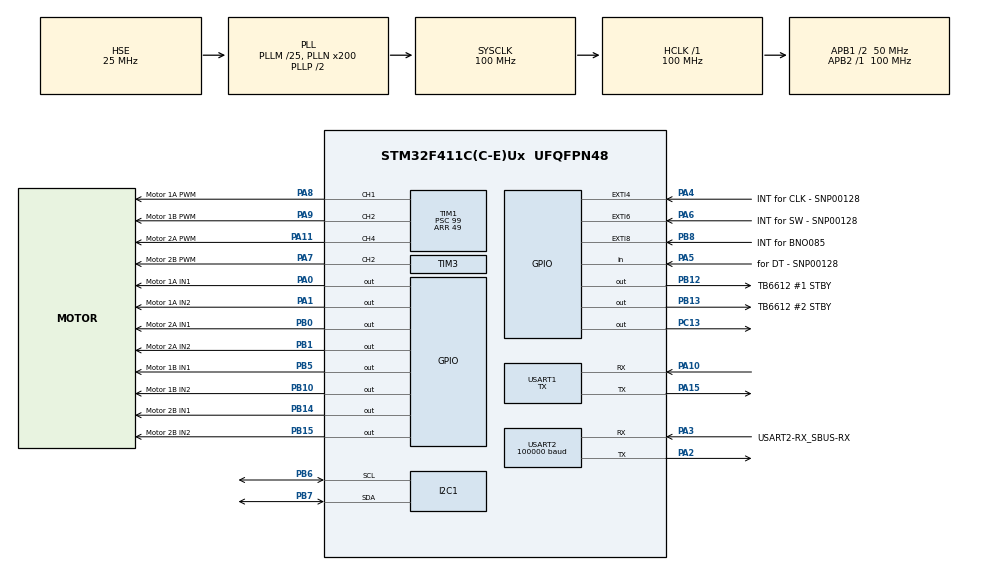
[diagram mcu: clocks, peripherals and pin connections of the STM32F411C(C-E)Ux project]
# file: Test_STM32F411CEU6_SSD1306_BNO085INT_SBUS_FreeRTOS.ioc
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Dma.Request0=USART2_RX
Dma.USART2_RX.0.Direction=DMA_PERIPH_TO_MEMORY
Dma.USART2_RX.0.FIFOMode=DMA_FIFOMODE_DISABLE
Dma.USART2_RX.0.Instance=DMA1_Stream5
Dma.USART2_RX.0.MemDataAlignment=DMA_MDATAALIGN_BYTE
Dma.USART2_RX.0.MemInc=DMA_MINC_ENABLE
Dma.USART2_RX.0.Mode=DMA_CIRCULAR
Dma.USART2_RX.0.PeriphDataAlignment=DMA_PDATAALIGN_BYTE
Dma.USART2_RX.0.PeriphInc=DMA_PINC_DISABLE
Dma.USART2_RX.0.Priority=DMA_PRIORITY_HIGH
FREERTOS.Mutexes01=CompassMutex,Dynamic,NULL,Depleted;I2C1Mutex,Dynamic,NULL,Depleted;EncoderMutex,Dynamic,NULL,Depleted;UARTMutex,Dynamic,NULL,Depleted;ModeMutex,Dynamic,NULL,Depleted;EEPROMMutex,Dynamic,NULL,Available
FREERTOS.Tasks01=defaultTask,32,256,StartDefaultTask,Default,NULL,Dynamic,NULL,NULL;CompassTask,40,256,StartCompassTask,Default,NULL,Dynamic,NULL,NULL;DisplayTask,8,320,StartDisplayTask,Default,NULL,Dynamic,NULL,NULL;EncoderTask,24,128,StartEncoderTask,Default,NULL,Dynamic,NULL,NULL
FREERTOS.configCHECK_FOR_STACK_OVERFLOW=1
FREERTOS.configENABLE_BACKWARD_COMPATIBILITY=0
FREERTOS.configGENERATE_RUN_TIME_STATS=1
FREERTOS.configUSE_APPLICATION_TASK_TAG=1
FREERTOS.configUSE_NEWLIB_REENTRANT=1
I2C1.DutyCycle=I2C_DUTYCYCLE_16_9
I2C1.I2C_Mode=I2C_Fast
IWDG.Prescaler=IWDG_PRESCALER_64
IWDG.Reload=3125
Mcu.Family=STM32F4
Mcu.Name=STM32F411C(C-E)Ux
Mcu.Package=UFQFPN48
NVIC.DMA1_Stream5_IRQn=true\:5\:0\:false\:false\:true\:true\:false\:true\:true
NVIC.EXTI4_IRQn=true\:5\:0\:false\:false\:true\:true\:true\:true\:true
NVIC.EXTI9_5_IRQn=true\:5\:0\:false\:false\:true\:true\:true\:true\:true
NVIC.PriorityGroup=NVIC_PRIORITYGROUP_4
NVIC.TIM2_IRQn=true\:15\:0\:false\:false\:true\:false\:false\:true\:true
NVIC.TimeBase=TIM2_IRQn
NVIC.TimeBaseIP=TIM2
NVIC.USART2_IRQn=true\:5\:0\:false\:false\:true\:true\:true\:true\:true
NimaLTD.I-CUBE-EE.3.2.2.DriverJjEE=true
NimaLTD.I-CUBE-EE.3.2.2.EE_MANUAL_CONFIG=true
NimaLTD.I-CUBE-EE.3.2.2.EE_SELECTED_ADDRESS=0x08070000
NimaLTD.I-CUBE-EE.3.2.2.EE_SELECTED_PAGE_SECTOR_NUMBER=7
NimaLTD.I-CUBE-EE.3.2.2.EE_SELECTED_PAGE_SECTOR_SIZE=EE_PAGE_SECTOR_SIZE_128K
PA0-WKUP.GPIO_Label=Motor 1A IN1
PA0-WKUP.Signal=GPIO_Output
PA1.GPIO_Label=Motor 1A IN2
PA1.Signal=GPIO_Output
PA10.Mode=Asynchronous
PA10.Signal=USART1_RX
PA11.GPIO_Label=Motor 2A PWM
PA11.Signal=S_TIM1_CH4
PA13.Mode=Serial_Wire
PA13.Signal=SYS_JTMS-SWDIO
PA14.Mode=Serial_Wire
PA14.Signal=SYS_JTCK-SWCLK
PA15.Mode=Asynchronous
PA15.Signal=USART1_TX
PA2.Mode=Asynchronous
PA2.Signal=USART2_TX
PA3.GPIO_Label=USART2-RX_SBUS-RX
PA3.GPIO_PuPd=GPIO_PULLUP
PA3.Mode=Asynchronous
PA3.Signal=USART2_RX
PA4.GPIO_Label=INT for CLK - SNP00128
PA4.GPIO_ModeDefaultEXTI=GPIO_MODE_IT_RISING_FALLING
PA4.GPIO_PuPd=GPIO_PULLUP
PA4.Signal=GPXTI4
PA5.GPIO_Label=for DT - SNP00128
PA5.GPIO_PuPd=GPIO_PULLUP
PA5.Signal=GPIO_Input
PA6.GPIO_Label=INT for SW - SNP00128
PA6.GPIO_ModeDefaultEXTI=GPIO_MODE_IT_FALLING
PA6.GPIO_PuPd=GPIO_PULLUP
PA6.Signal=GPXTI6
PA7.GPIO_Label=Motor 2B PWM
PA7.Signal=S_TIM3_CH2
PA8.GPIO_Label=Motor 1A PWM
PA8.Signal=S_TIM1_CH1
PA9.GPIO_Label=Motor 1B PWM
PA9.Signal=S_TIM1_CH2
PB0.GPIO_Label=Motor 2A IN1
PB0.Signal=GPIO_Output
PB1.GPIO_Label=Motor 2A IN2
PB1.Signal=GPIO_Output
PB10.GPIO_Label=Motor 1B IN2
PB10.Signal=GPIO_Output
PB12.GPIO_Label=TB6612 \#1 STBY
PB12.Signal=GPIO_Output
PB13.GPIO_Label=TB6612 \#2 STBY
PB13.Signal=GPIO_Output
PB14.GPIO_Label=Motor 2B IN1
PB14.Signal=GPIO_Output
PB15.GPIO_Label=Motor 2B IN2
PB15.Signal=GPIO_Output
PB5.GPIO_Label=Motor 1B IN1
PB5.Signal=GPIO_Output
PB6.Mode=I2C
PB6.Signal=I2C1_SCL
PB7.Mode=I2C
PB7.Signal=I2C1_SDA
PB8.GPIO_Label=INT for BNO085
PB8.GPIO_ModeDefaultEXTI=GPIO_MODE_IT_FALLING
PB8.Signal=GPXTI8
PC13-ANTI_TAMP.Signal=GPIO_Output
PH0\ -\ OSC_IN.Mode=HSE-External-Oscillator
PH0\ -\ OSC_IN.Signal=RCC_OSC_IN
PH1\ -\ OSC_OUT.Mode=HSE-External-Oscillator
PH1\ -\ OSC_OUT.Signal=RCC_OSC_OUT
ProjectManager.HeapSize=0x200
ProjectManager.StackSize=0x400
ProjectManager.TargetToolchain=STM32CubeIDE
RCC.48MHZClocksFreq_Value=50000000
RCC.AHBFreq_Value=100000000
RCC.APB1CLKDivider=RCC_HCLK_DIV2
RCC.APB1Freq_Value=50000000
RCC.APB1TimFreq_Value=100000000
RCC.APB2Freq_Value=100000000
RCC.APB2TimFreq_Value=100000000
RCC.CortexFreq_Value=100000000
RCC.HCLKFreq_Value=100000000
RCC.HSE_VALUE=25000000
RCC.HSI_VALUE=16000000
RCC.LSE_VALUE=32768
RCC.PLLM=25
RCC.PLLN=200
RCC.PLLSourceVirtual=RCC_PLLSOURCE_HSE
RCC.SYSCLKFreq_VALUE=100000000
RCC.SYSCLKSource=RCC_SYSCLKSOURCE_PLLCLK
RCC.VCOOutputFreq_Value=200000000
SH.S_TIM1_CH1.0=TIM1_CH1,PWM Generation1 CH1
SH.S_TIM1_CH2.0=TIM1_CH2,PWM Generation2 CH2
SH.S_TIM1_CH4.0=TIM1_CH4,PWM Generation4 CH4
SH.S_TIM3_CH2.0=TIM3_CH2,PWM Generation2 CH2
TIM1.Channel-PWM\ Generation1\ CH1=TIM_CHANNEL_1
TIM1.Channel-PWM\ Generation2\ CH2=TIM_CHANNEL_2
TIM1.Channel-PWM\ Generation4\ CH4=TIM_CHANNEL_4
TIM1.Period=49
TIM1.Prescaler=99
TIM3.Channel-PWM\ Generation2\ CH2=TIM_CHANNEL_2
TIM3.Period=49
TIM3.Prescaler=99
USART1.Mode=MODE_TX
USART1.VirtualMode=VM_ASYNC
USART2.BaudRate=100000
USART2.Mode=MODE_RX
USART2.Parity=PARITY_EVEN
USART2.StopBits=STOPBITS_2
USART2.VirtualMode=VM_ASYNC
USART2.WordLength=WORDLENGTH_9B
VP_FREERTOS_VS_CMSIS_V2.Mode=CMSIS_V2
VP_IWDG_VS_IWDG.Mode=IWDG_Activate
VP_NimaLTD.I-CUBE-EE_VS_DriverJjEE_1.0.0_3.2.2.Mode=DriverJjEE
VP_SYS_VS_tim2.Mode=TIM2
board=custom

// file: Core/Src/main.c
/* USER CODE BEGIN Header */
/**
 ******************************************************************************
 * @file           : main.c
 * @brief          : Main program body
 ******************************************************************************
 * @attention
 *
 * Copyright (c) 2025 STMicroelectronics.
 * All rights reserved.
 *
 * This software is licensed under terms that can be found in the LICENSE file
 * in the root directory of this software component.
 * If no LICENSE file comes with this software, it is provided AS-IS.
 *
 ******************************************************************************
 */

// Compiler optimizations for performance-critical functions
#pragma GCC optimize("O3")
#pragma GCC target("thumb")
/* USER CODE END Header */
#include "main.h"
#include "cmsis_os.h"

/* USER CODE BEGIN Includes */
#include "ssd1306.h"
#include "fonts.h"
#include <string.h>
#include <stdio.h>
#include <stdarg.h>
#include <math.h>
#include "sh2/sh2.h"
#include "sh2/sh2_SensorValue.h"
#include "sh2/sh2_platform_impl.h"
#include "tb6612fng.h"
//#include "ee.h"
#include "mb85rc256v.h"
/* USER CODE END Includes */

/* USER CODE BEGIN PD */
#define ENCODER_DEBOUNCE_MS 150
#define BUTTON_DEBOUNCE_MS 400
#define CLK_SW_DEBOUNCE_MS 30
#define SBUS_FRAME_SIZE 25

// Robot operation modes
typedef enum {
	MODE_DISPLAY_SENSORS = 0, MODE_MOVEMENT = 1, // Robot movement w/o heading lock
	MODE_MOVEMENT_HL = 2,     // Robot movement with heading lock
	MODE_COUNT = 3
} robot_mode_t;

// Robot states
typedef enum {
	STATE_IDLE = 0, STATE_RUNNING = 1
} robot_state_t;

// SBUS Channel 7 mode control with dead zones
typedef enum {
	CH7_POSITION_MIN = 0,
	CH7_POSITION_MID = 1,
	CH7_POSITION_MAX = 2,
	CH7_POSITION_UNKNOWN = 3
} ch7_position_t;

/* USER CODE END PD */

I2C_HandleTypeDef hi2c1;

IWDG_HandleTypeDef hiwdg;

TIM_HandleTypeDef htim1;
TIM_HandleTypeDef htim3;

UART_HandleTypeDef huart1;
UART_HandleTypeDef huart2;
DMA_HandleTypeDef hdma_usart2_rx;

/* Definitions for defaultTask */
osThreadId_t defaultTaskHandle;
const osThreadAttr_t defaultTask_attributes = {
  .name = "defaultTask",
  .stack_size = 256 * 4,
  .priority = (osPriority_t) osPriorityAboveNormal,
};
/* Definitions for CompassTask */
osThreadId_t CompassTaskHandle;
const osThreadAttr_t CompassTask_attributes = {
  .name = "CompassTask",
  .stack_size = 256 * 4,
  .priority = (osPriority_t) osPriorityHigh,
};
/* Definitions for DisplayTask */
osThreadId_t DisplayTaskHandle;
const osThreadAttr_t DisplayTask_attributes = {
  .name = "DisplayTask",
  .stack_size = 320 * 4,
  .priority = (osPriority_t) osPriorityLow,
};
/* Definitions for EncoderTask */
osThreadId_t EncoderTaskHandle;
const osThreadAttr_t EncoderTask_attributes = {
  .name = "EncoderTask",
  .stack_size = 128 * 4,
  .priority = (osPriority_t) osPriorityNormal,
};
/* Definitions for CompassMutex */
osMutexId_t CompassMutexHandle;
const osMutexAttr_t CompassMutex_attributes = {
  .name = "CompassMutex"
};
/* Definitions for I2C1Mutex */
osMutexId_t I2C1MutexHandle;
const osMutexAttr_t I2C1Mutex_attributes = {
  .name = "I2C1Mutex"
};
/* Definitions for EncoderMutex */
osMutexId_t EncoderMutexHandle;
const osMutexAttr_t EncoderMutex_attributes = {
  .name = "EncoderMutex"
};
/* Definitions for UARTMutex */
osMutexId_t UARTMutexHandle;
const osMutexAttr_t UARTMutex_attributes = {
  .name = "UARTMutex"
};
/* Definitions for ModeMutex */
osMutexId_t ModeMutexHandle;
const osMutexAttr_t ModeMutex_attributes = {
  .name = "ModeMutex"
};
/* Definitions for EEPROMMutex */
osMutexId_t EEPROMMutexHandle;
const osMutexAttr_t EEPROMMutex_attributes = {
  .name = "EEPROMMutex"
};
/* USER CODE BEGIN PV */
// USART
uint8_t sbus_rx_buffer[SBUS_FRAME_SIZE];
volatile uint16_t sbus_channels[16] = { 0 };
volatile uint32_t uart2_error_code = 0;
volatile uint8_t uart2_error_flag = 0;
// SBUS signal monitoring
volatile uint32_t sbus_last_valid_time = 0;
volatile uint8_t sbus_signal_valid = 0;
#define SBUS_TIMEOUT_MS 100  // Stop motors if no valid SBUS for 100ms
// SBUS recovery variables
volatile uint8_t sbus_recovery_attempts = 0;
volatile uint32_t sbus_last_error_time = 0;
volatile uint8_t sbus_recovery_requested = 0;
#define SBUS_MAX_RECOVERY_ATTEMPTS 5
#define SBUS_ERROR_COOLDOWN_MS 1000
// Compass variables
volatile uint8_t bno085_int_flag = 0;
volatile float compass_heading_deg = 0.0f;
// Encoder variables
volatile int32_t encoder_count = 0;
volatile uint8_t encoder_button_pressed = 0;
volatile int32_t encoder_sw_count = 0;
uint32_t last_clk_tick = 0;
uint32_t last_sw_tick = 0;

// Mode control variables
volatile robot_mode_t current_mode = MODE_DISPLAY_SENSORS;
volatile robot_mode_t selected_mode = MODE_DISPLAY_SENSORS;
volatile robot_state_t robot_state = STATE_IDLE;
volatile uint8_t mode_change_request = 0;
volatile uint8_t state_toggle_request = 0;

// Motor control variables for 3-wheel omnidirectional robot
volatile int16_t joystick_x = 0;          // Left/Right (-100 to +100)
volatile int16_t joystick_y = 0;          // Forward/Backward (-100 to +100)
volatile int16_t joystick_rotation = 0;   // Rotation (-100 to +100)
volatile int16_t motor_left_front = 0;    // Motor 1B (Left Front)
volatile int16_t motor_right_front = 0;   // Motor 1A (Right Front)
volatile int16_t motor_back = 0;          // Motor 2A (Back)

// Heading lock and PID control variables
volatile uint8_t heading_lock_enabled = 0;
volatile float locked_heading = 0.0f;
volatile float heading_error = 0.0f;
volatile float heading_pid_output = 0.0f;

// PID parameters for heading control - Optimized based on testing
#define PID_KP 0.35f   // Reduced from 0.7f (based on your optimal -0.5 adjustment)
#define PID_KI 0.02f   // Keep same - was working well
#define PID_KD 0.67f   // Optimal base value (was giving best results at 0 adjustment)
//#define PID_MAX_OUTPUT 15.0f  // Limited to 15% for gentle correction
#define PID_MAX_OUTPUT 18.0f  // Limited to 18% for gentle correction
#define PID_INTEGRAL_MAX 20.0f  // Reduced anti-windup limit

// PID state variables
volatile float pid_integral = 0.0f;
volatile float pid_previous_error = 0.0f;
volatile uint32_t pid_last_time = 0;

// Overshoot detection variables
volatile float pid_last_error_direction = 0.0f;
volatile uint8_t overshoot_detected = 0;
volatile uint8_t oscillation_detected = 0;  // ADD THIS LINE

// Rate limiting for smooth PID output
volatile float pid_output_filtered = 0.0f;
#define PID_RATE_LIMIT 2.0f  // Max change per update cycle (2%/cycle)

// SBUS recovery state tracking
volatile uint8_t sbus_was_lost = 0;         // Track if SBUS was previously lost
volatile uint8_t heading_lock_was_enabled = 0; // Remember if heading lock was enabled before SBUS loss

// Robot orientation offset - BNO085 sensor mounting compensation
#define ROBOT_FRONT_OFFSET 282.0f  // 102° + 180° = 282°

typedef struct {
	uint32_t magic_number;           // Validation marker
	float saved_locked_heading;      // Last locked heading value
	uint8_t heading_lock_was_active; // Was heading lock active when saved
} eeStorage_t;

eeStorage_t eeStorage = { 0, 0.0f, 0 }; // magic_number, saved_locked_heading, heading_lock_was_active

#define EE_MAGIC_NUMBER 0x48454144  // "HEAD" in hex

// Exception tracking variables
typedef struct {
    uint32_t exception_count;
    uint32_t last_exception_time;
    uint32_t last_exception_lr;    // Link Register
    uint32_t last_exception_pc;    // Program Counter
    uint8_t last_exception_type;   // Exception type
    uint32_t last_i2c_error;      // I2C error code
    uint32_t i2c_error_count;     // I2C error counter
} exception_info_t;

volatile exception_info_t exception_info = {0, 0, 0, 0, 0, 0, 0};

#define EXCEPTION_HARDFAULT   1
#define EXCEPTION_MEMFAULT    2
#define EXCEPTION_BUSFAULT    3
#define EXCEPTION_USAGEFAULT  4
#define EXCEPTION_ASSERT      5
#define EXCEPTION_I2C_ERROR   6

// SH2 HAL glue
sh2_Hal_t sh2_hal;
sh2_SensorConfig_t sh2_config;
/* USER CODE END PV */

void SystemClock_Config(void);
static void MX_GPIO_Init(void);
static void MX_DMA_Init(void);
static void MX_I2C1_Init(void);
static void MX_USART2_UART_Init(void);
static void MX_TIM1_Init(void);
static void MX_TIM3_Init(void);
static void MX_IWDG_Init(void);
static void MX_USART1_UART_Init(void);
void StartDefaultTask(void *argument);
void StartCompassTask(void *argument);
void StartDisplayTask(void *argument);
void StartEncoderTask(void *argument);
void print_system_status(void);
/* USER CODE BEGIN PFP */
// Function prototypes
float compass_to_robot_front(float compass_heading);
float get_robot_front_heading(void);
void set_heading_lock(float compass_heading);
void disable_heading_lock(void);
float calculate_heading_pid_simplified(float target_heading,
		float current_heading);
void reset_heading_pid(void);
float angle_difference(float target, float current);
uint8_t is_sbus_signal_valid(void);
void save_heading_lock_to_eeprom(void);
bool restore_heading_lock_from_eeprom(void);
void record_exception(uint8_t type, uint32_t lr, uint32_t pc);
void record_i2c_exception(uint32_t i2c_error_code);
void record_hardfault(uint32_t *stack_ptr, uint32_t pc, uint32_t lr);
HAL_StatusTypeDef MB85rc_Bus_Write_Safe(uint16_t DevAddress, uint16_t MemAddress, uint8_t *pData, uint16_t Size);
HAL_StatusTypeDef MB85rc_Bus_Read_Safe(uint16_t DevAddress, uint16_t MemAddress, uint8_t *pData, uint16_t Size);
/* USER CODE END PFP */

/* USER CODE BEGIN 0 */

// Printf redirection for USART1
int _write(int file, char *ptr, int len) {
	HAL_UART_Transmit(&huart1, (uint8_t*)ptr, len, 1000);
	return len;
}

// Alternative function for direct debug printing
void debug_print(const char* format, ...) {
	char buffer[256];
	va_list args;
	va_start(args, format);
	vsnprintf(buffer, sizeof(buffer), format, args);
	va_end(args);
	HAL_UART_Transmit(&huart1, (uint8_t*)buffer, strlen(buffer), 1000);
}

// Modified I2C bus scanner: stores found addresses in a string buffer
void i2c_bus_scan(char *found_devices, size_t bufsize) {
	char addr_str[8];
	uint8_t first = 1;
	found_devices[0] = '\0';

	for (uint8_t addr = 1; addr < 127; addr++) {
		if (HAL_I2C_IsDeviceReady(&hi2c1, addr << 1, 1, 10) == HAL_OK) {
			if (!first) {
				strncat(found_devices, ",",
						bufsize - strlen(found_devices) - 1);
			}
			snprintf(addr_str, sizeof(addr_str), "0x%02X", addr);
			strncat(found_devices, addr_str,
					bufsize - strlen(found_devices) - 1);
			first = 0;
		}
	}
}

// Read BNO085 Chip ID register (Register 0x00)
uint8_t bno085_read_chip_id() {
	uint8_t reg = 0x00;
	uint8_t id = 0;
	if (HAL_I2C_Master_Transmit(&hi2c1, BNO085_ADDR, &reg, 1, HAL_MAX_DELAY)
			!= HAL_OK)
		return 0xFF; // Indicate error
	if (HAL_I2C_Master_Receive(&hi2c1, BNO085_ADDR, &id, 1, HAL_MAX_DELAY)
			!= HAL_OK)
		return 0xFF; // Indicate error
	return id;
}

void sh2_event_callback(void *cookie, sh2_AsyncEvent_t *pEvent) {
	// Optional: handle async events (reset, etc.)
}

static void sh2_sensor_handler(void *cookie, sh2_SensorEvent_t *event) {
	// Handle sensor events from BNO085
	sh2_SensorValue_t value;
	if (sh2_decodeSensorEvent(&value, event) == 0) {
		if (value.sensorId == SH2_ROTATION_VECTOR) {
			float q0 = value.un.rotationVector.real;
			float q1 = value.un.rotationVector.i;
			float q2 = value.un.rotationVector.j;
			float q3 = value.un.rotationVector.k;
			float t3 = 2.0f * (q0 * q3 + q1 * q2);
			float t4 = 1.0f - 2.0f * (q2 * q2 + q3 * q3);
			float yaw = atan2f(t3, t4);
			float yaw_deg = yaw * (180.0f / (float) M_PI);
			if (yaw_deg < 0)
				yaw_deg += 360.0f;
			osMutexAcquire(CompassMutexHandle, osWaitForever);
			compass_heading_deg = yaw_deg;
			osMutexRelease(CompassMutexHandle);
		}
	}
}

void bno085_setup(void) {
	sh2_hal.open = sh2_hal_open;
	sh2_hal.close = sh2_hal_close;
	sh2_hal.read = sh2_hal_read;
	sh2_hal.write = sh2_hal_write;
	sh2_hal.getTimeUs = sh2_hal_getTimeUs;

	sh2_open(&sh2_hal, sh2_event_callback, NULL);
	sh2_setSensorCallback(sh2_sensor_handler, NULL);

	sh2_config.changeSensitivityEnabled = false;
	sh2_config.changeSensitivityRelative = false;
	sh2_config.wakeupEnabled = false;
	sh2_config.alwaysOnEnabled = false;
	sh2_config.sniffEnabled = false;
	sh2_config.changeSensitivity = 0;
	sh2_config.reportInterval_us = 10000; // 100Hz
	//sh2_config.reportInterval_us = 20000; // 50Hz
	sh2_config.batchInterval_us = 0;
	sh2_config.sensorSpecific = 0;

	sh2_setSensorConfig(SH2_ROTATION_VECTOR, &sh2_config);
}

// Convert SBUS channel value (172-1811) to percentage (-100 to +100)
int16_t sbus_to_percentage(uint16_t sbus_value) {
	if (sbus_value < 172)
		sbus_value = 172;
	if (sbus_value > 1811)
		sbus_value = 1811;

	int16_t result = (int16_t) (((int32_t) sbus_value - 992) * 100 / 820);

	// Optional: Dead zone of ±5%
	if (result >= -5 && result <= 5) {
		result = 0;
	}

	return result;
}

// Calculate individual motor speeds for 3-wheel omnidirectional robot
// x: Left/Right movement (-100 to +100) - Positive = Right, Negative = Left
// y: Forward/Backward movement (-100 to +100) - Positive = Forward, Negative = Backward
// rotation: Rotational movement (-100 to +100) - Positive = Clockwise, Negative = Counter-clockwise
void calculate_omni_motor_speeds(int16_t x, int16_t y, int16_t rotation,
		int16_t *left_front, int16_t *right_front, int16_t *back) {
	// 3-wheel omnidirectional kinematics - CORRECTED ROTATION DIRECTION
	// For 120-degree spaced wheels:
	// Left Front (Motor 1B):   +0.5*x + 0.866*y - rotation  (FIXED: was +rotation)
	// Right Front (Motor 1A):  +0.5*x - 0.866*y - rotation  (FIXED: was +rotation)
	// Back (Motor 2A):         -1.0*x + 0*y - rotation      (FIXED: was +rotation)

	// Use integer math (multiply by 100 to maintain precision, then divide)
	int32_t lf = (+50 * x + 87 * y - 100 * rotation) / 100; // Left Front (FIXED)
	int32_t rf = (+50 * x - 87 * y - 100 * rotation) / 100; // Right Front (FIXED)
	int32_t bk = (-100 * x + 0 * y - 100 * rotation) / 100;  // Back (FIXED)

	// Clamp to -100 to +100
	if (lf > 100)
		lf = 100;
	if (lf < -100)
		lf = -100;
	if (rf > 100)
		rf = 100;
	if (rf < -100)
		rf = -100;
	if (bk > 100)
		bk = 100;
	if (bk < -100)
		bk = -100;

	*left_front = (int16_t) lf;
	*right_front = (int16_t) rf;
	*back = (int16_t) bk;
}

// Calculate individual motor speeds for 3-wheel omnidirectional robot with heading lock
// x: Left/Right movement (-100 to +100) - Positive = Right, Negative = Left
// y: Forward/Backward movement (-100 to +100) - Positive = Forward, Negative = Backward
// rotation: Rotational movement (-100 to +100)
// heading_correction: PID output for heading lock (-100 to +100)
void calculate_omni_motor_speeds_with_heading(int16_t x, int16_t y,
		int16_t rotation, float heading_correction, int16_t *left_front,
		int16_t *right_front, int16_t *back) {

	// Blend manual rotation with heading correction
	// Give priority to manual input when operator is actively rotating
	float manual_rotation_f = (float) rotation;
	float total_rotation;

	if (fabs(manual_rotation_f) > 10.0f) {
		// Manual rotation is active - blend with less heading correction
		total_rotation = manual_rotation_f + (heading_correction * 0.3f);
	} else {
		// No manual rotation - use full heading correction
		total_rotation = manual_rotation_f + heading_correction;
	}

	// Clamp total rotation to prevent overflow
	if (total_rotation > 100.0f)
		total_rotation = 100.0f;
	if (total_rotation < -100.0f)
		total_rotation = -100.0f;

	// 3-wheel omnidirectional kinematics with heading correction - FIXED ROTATION
	int32_t lf = (+50 * x + 87 * y - (int32_t) total_rotation * 100) / 100; // FIXED
	int32_t rf = (+50 * x - 87 * y - (int32_t) total_rotation * 100) / 100; // FIXED
	int32_t bk = (-100 * x + 0 * y - (int32_t) total_rotation * 100) / 100; // FIXED

	// Clamp to -100 to +100
	if (lf > 100)
		lf = 100;
	if (lf < -100)
		lf = -100;
	if (rf > 100)
		rf = 100;
	if (rf < -100)
		rf = -100;
	if (bk > 100)
		bk = 100;
	if (bk < -100)
		bk = -100;

	*left_front = (int16_t) lf;
	*right_front = (int16_t) rf;
	*back = (int16_t) bk;
}

// Apply motor speeds to actual motors (3-wheel configuration)
void apply_motor_speeds_3wheel(int16_t left_front, int16_t right_front,
		int16_t back) {
	const uint16_t pwm_val1 = 49; // For TIM1 (100% duty if Period = 49)
	const uint16_t pwm_val3 = 49; // For TIM3 (was 24, now 49)

	// Motor 1B - Left Front
	if (left_front == 0) {
		tb6612fng_brake(MOTOR_1B);
	} else if (left_front > 0) {
		tb6612fng_drive(MOTOR_1B, TB6612FNG_FORWARD,
				(pwm_val1 * left_front) / 100);
	} else {
		tb6612fng_drive(MOTOR_1B, TB6612FNG_BACKWARD,
				(pwm_val1 * (-left_front)) / 100);
	}

	// Motor 1A - Right Front
	if (right_front == 0) {
		tb6612fng_brake(MOTOR_1A);
	} else if (right_front > 0) {
		tb6612fng_drive(MOTOR_1A, TB6612FNG_FORWARD,
				(pwm_val1 * right_front) / 100);
	} else {
		tb6612fng_drive(MOTOR_1A, TB6612FNG_BACKWARD,
				(pwm_val1 * (-right_front)) / 100);
	}

	// Motor 2A - Back
	if (back == 0) {
		tb6612fng_brake(MOTOR_2A);
	} else if (back > 0) {
		tb6612fng_drive(MOTOR_2A, TB6612FNG_FORWARD, (pwm_val3 * back) / 100);
	} else {
		tb6612fng_drive(MOTOR_2A, TB6612FNG_BACKWARD,
				(pwm_val3 * (-back)) / 100);
	}
}

// Stop all motors (3-wheel configuration)
void stop_all_motors_3wheel(void) {
	tb6612fng_stop(MOTOR_1A); // Right Front
	tb6612fng_stop(MOTOR_1B); // Left Front
	tb6612fng_stop(MOTOR_2A); // Back
}

// Check if SBUS signal is valid and recent
// Enhanced SBUS signal check with recovery
uint8_t is_sbus_signal_valid(void) {
	uint32_t now = HAL_GetTick();

	// Check if we have received a valid frame recently
	if (sbus_signal_valid && (now - sbus_last_valid_time) <= SBUS_TIMEOUT_MS) {
		return 1;
	} else {
		sbus_signal_valid = 0; // Mark as invalid if timeout

		// If signal has been lost for a long time, try recovery
		if ((now - sbus_last_valid_time) > (SBUS_TIMEOUT_MS * 10)) {
			// Signal lost for 1 second - attempt recovery
			static uint32_t last_recovery_attempt = 0;
			if ((now - last_recovery_attempt) > 5000) {  // Try every 5 seconds
				last_recovery_attempt = now;

				// Reinitialize UART from main context (safer than interrupt)
				HAL_UART_AbortReceive(&huart2);
				MX_USART2_UART_Init();
				HAL_UART_Receive_DMA(&huart2, sbus_rx_buffer, SBUS_FRAME_SIZE);
			}
		}

		return 0;
	}
}

// Calculate shortest angle difference (handles 0-360 wrap-around)
float angle_difference(float target, float current) {
	float diff = target - current;

	// Normalize to -180 to +180 range
	while (diff > 180.0f)
		diff -= 360.0f;
	while (diff < -180.0f)
		diff += 360.0f;

	return diff;
}

// Simplified PID controller with reduced computational overhead
float calculate_heading_pid_simplified(float target_heading,
		float current_heading) {
	static float integral = 0.0f;
	static float previous_error = 0.0f;
	static float output_filtered = 0.0f;
	static uint32_t last_time = 0;
	static float error_history[3] = { 0 }; // Reduced from 5 to 3
	static uint8_t history_idx = 0;
	static uint32_t last_oscillation_time = 0;
	static uint32_t overshoot_cooldown = 0;
	static float derivative_filtered = 0.0f; // Add filtered derivative
	static float motion_factor = 1.0f; // Motion detection factor

	uint32_t now = HAL_GetTick();
	if (last_time == 0)
		last_time = now;

	float dt = (now - last_time) / 1000.0f;
	if (dt <= 0)
		return output_filtered;

	// Calculate error with angle wrapping
	float error = target_heading - current_heading;
	while (error > 180.0f)
		error -= 360.0f;
	while (error < -180.0f)
		error += 360.0f;

	// Store error in simplified history
	error_history[history_idx] = error;
	history_idx = (history_idx + 1) % 3;

	// Simplified oscillation detection (check only last 3 samples)
	uint8_t oscillation = 0;
	if (fabs(error) < 20.0f) { // Only check when close to target
		int sign_changes = 0;
		for (int i = 0; i < 2; i++) {
			if ((error_history[i] * error_history[i + 1]) < 0) {
				sign_changes++;
			}
		}
		if (sign_changes >= 1 && (now - last_oscillation_time) > 1000) {
			oscillation = 1;
			last_oscillation_time = now;
			integral *= 0.5f; // Reduce integral windup
		}
	}

	// Simplified overshoot detection
	uint8_t overshoot = 0;
	if ((previous_error * error) < 0 && fabs(error) > 15.0f) {
		if ((now - overshoot_cooldown) > 1000) {
			overshoot = 1;
			overshoot_cooldown = now;
			integral *= 0.7f;
		}
	}

	// Simplified dead zone
	float dead_zone = oscillation ? 4.0f : (overshoot ? 2.0f : 1.0f);

	if (fabs(error) < dead_zone) {
		// Gentle decay near target
		integral *= 0.95f;
		output_filtered *= 0.9f;
		previous_error = error;
		last_time = now;
		return output_filtered;
	}

	// Motion detection to reduce derivative gain when stationary
	// Check if robot is actually moving based on joystick inputs
	extern volatile int16_t joystick_x, joystick_y, joystick_rotation;
	float total_motion = fabs((float)joystick_x) + fabs((float)joystick_y) + fabs((float)joystick_rotation);

	// Update motion factor with filtering
	float target_motion_factor;
	if (total_motion > 20.0f) {
		// Robot is moving - use full derivative gain
		target_motion_factor = 1.0f;
	} else if (total_motion > 5.0f) {
		// Gentle movement - moderate derivative gain
		target_motion_factor = 0.7f;
	} else {
		// Stationary - reduce derivative gain to minimize noise amplification
		target_motion_factor = 0.3f;
	}

	// Smooth motion factor changes
	float motion_alpha = 0.1f; // Slow adaptation
	motion_factor = motion_alpha * target_motion_factor + (1.0f - motion_alpha) * motion_factor;

	// Optimized adaptive gains based on testing results
	float kp, ki, kd, max_output;
	if (fabs(error) > 60.0f) {
		kp = 0.5f;   // Keep reduced Kp
		ki = 0.02f;
		kd = 0.67f;  // Optimal base value from testing
		max_output = 25.0f;
	} else if (fabs(error) > 20.0f) {
		kp = 0.75f;  // Keep reduced Kp
		ki = 0.03f;
		kd = 1.0f;   // Optimal scaled value from testing
		max_output = 20.0f;
	} else {
		kp = 1.0f;   // Keep reduced Kp
		ki = 0.04f;
		kd = 1.33f;  // Optimal scaled value from testing
		max_output = 15.0f;
	}

	// Apply motion factor to reduce noise when stationary
	kd = kd * motion_factor;

	// Reduce gains if problems detected
	if (overshoot) {
		kp *= 0.7f;
		ki *= 0.5f;
		kd *= 0.8f;
		max_output *= 0.8f;
	}
	if (oscillation) {
		kp *= 0.5f;
		ki *= 0.3f;
		kd *= 0.6f;
		max_output *= 0.7f;
	}

	// Calculate PID terms with derivative filtering
	float proportional = kp * error;

	integral += error * dt;
	integral = fmaxf(-50.0f, fminf(50.0f, integral)); // Simple clamping
	float integral_term = ki * integral;

	// Calculate raw derivative
	float derivative_raw = kd * (error - previous_error) / dt;

	// Apply low-pass filter to derivative to reduce jerkiness
	float derivative_alpha = 0.3f; // Filter strength (0.1 = heavy filtering, 0.9 = light filtering)
	derivative_filtered = derivative_alpha * derivative_raw + (1.0f - derivative_alpha) * derivative_filtered;

	float raw_output = proportional + integral_term + derivative_filtered;

	// Simple output limiting
	raw_output = fmaxf(-max_output, fminf(max_output, raw_output));

	// Improved rate limiting for smoother response
	float rate_limit = fabs(error) > 30.0f ? 1.5f : 2.5f; // Reduced for smoother response
	if (overshoot)
		rate_limit *= 0.6f; // More aggressive rate limiting after overshoot
	if (oscillation)
		rate_limit *= 0.4f; // More aggressive rate limiting during oscillation

	// Additional smoothing based on derivative magnitude
	if (fabs(derivative_filtered) > 5.0f) {
		rate_limit *= 0.7f; // Reduce rate limit when derivative is high
	}

	float output_diff = raw_output - output_filtered;
	if (fabs(output_diff) > rate_limit) {
		output_diff = (output_diff > 0) ? rate_limit : -rate_limit;
	}
	output_filtered += output_diff;

	// Simple approach damping for small errors
	if (fabs(error) < 20.0f && fabs(error) > 3.0f) {
		float approach_factor = fabs(error) / 20.0f;
		if (approach_factor < 0.6f)
			approach_factor = 0.6f;
		output_filtered *= approach_factor;
	}

	// Update for next iteration
	previous_error = error;
	last_time = now;

	// Store for debugging
	heading_error = error;
	heading_pid_output = output_filtered;

	return output_filtered;
}

// Reset PID controller
void reset_heading_pid(void) {
	pid_integral = 0.0f;
	pid_previous_error = 0.0f;
	pid_output_filtered = 0.0f;  // Reset filtered output
	pid_last_time = HAL_GetTick();
	heading_error = 0.0f;
	heading_pid_output = 0.0f;
}
// Updated set heading lock function
void set_heading_lock(float compass_heading) {
	locked_heading = compass_to_robot_front(compass_heading);
	heading_lock_enabled = 1;
	reset_heading_pid();
	save_heading_lock_to_eeprom(); // Add this line
}

// Disable heading lock
void disable_heading_lock(void) {
	heading_lock_enabled = 0;
	reset_heading_pid();
}

// Convert compass heading to robot front direction
float compass_to_robot_front(float compass_heading) {
	float robot_front = compass_heading + ROBOT_FRONT_OFFSET;

	// Normalize to 0-360 range
	while (robot_front >= 360.0f) {
		robot_front -= 360.0f;
	}
	while (robot_front < 0.0f) {
		robot_front += 360.0f;
	}

	return robot_front;
}

// Get current robot front direction
float get_robot_front_heading(void) {
	float compass_heading;

	osMutexAcquire(CompassMutexHandle, osWaitForever);
	compass_heading = compass_heading_deg;
	osMutexRelease(CompassMutexHandle);

	return compass_to_robot_front(compass_heading);
}

/*
 // EEPROM storage functions for heading lock
 void save_heading_lock_to_eeprom(void) {
 if (heading_lock_enabled) {
 osMutexAcquire(EEPROMMutexHandle, osWaitForever);
 eeStorage.magic_number = EE_MAGIC_NUMBER;
 eeStorage.saved_locked_heading = locked_heading;
 eeStorage.heading_lock_was_active = 1;
 EE_Write();
 osMutexRelease(EEPROMMutexHandle);
 }
 }

 bool restore_heading_lock_from_eeprom(void) {
 bool result = false;
 osMutexAcquire(EEPROMMutexHandle, osWaitForever);
 EE_Read();
 if (eeStorage.magic_number == EE_MAGIC_NUMBER
 && eeStorage.heading_lock_was_active) {
 locked_heading = eeStorage.saved_locked_heading;
 result = true;
 }
 osMutexRelease(EEPROMMutexHandle);
 return result;
 }
 */

// Exception handling functions
void record_exception(uint8_t type, uint32_t lr, uint32_t pc) {
    exception_info.exception_count++;
    exception_info.last_exception_time = HAL_GetTick();
    exception_info.last_exception_lr = lr;
    exception_info.last_exception_pc = pc;
    exception_info.last_exception_type = type;
}

void record_i2c_exception(uint32_t i2c_error_code) {
    exception_info.exception_count++;
    exception_info.i2c_error_count++;
    exception_info.last_exception_time = HAL_GetTick();
    exception_info.last_exception_type = EXCEPTION_I2C_ERROR;
    exception_info.last_i2c_error = i2c_error_code;
}

void record_hardfault(uint32_t *stack_ptr, uint32_t pc, uint32_t lr) {
    record_exception(EXCEPTION_HARDFAULT, lr, pc);

    // Try to recover instead of hanging
    HAL_GPIO_WritePin(GPIOC, GPIO_PIN_13, GPIO_PIN_RESET); // Turn on LED

    // Log the fault
    printf("HardFault: PC=0x%08lX, LR=0x%08lX, Count=%lu\r\n",
           pc, lr, exception_info.exception_count);

    // Reset system after logging
    HAL_Delay(100);
    NVIC_SystemReset();
}

// Enhanced HardFault handler
void HardFault_Handler(void) {
    __asm volatile (
        "tst lr, #4 \n"
        "ite eq \n"
        "mrseq r0, msp \n"
        "mrsne r0, psp \n"
        "ldr r1, [r0, #24] \n"
        "mov r2, lr \n"
        "bl record_hardfault \n"
        "b . \n"
    );
}

// Safe I2C functions with error tracking
HAL_StatusTypeDef MB85rc_Bus_Write_Safe(uint16_t DevAddress, uint16_t MemAddress, uint8_t *pData, uint16_t Size) {
    HAL_StatusTypeDef status = MB85rc_Bus_Write(DevAddress, MemAddress, pData, Size);
    if (status != HAL_OK) {
        record_i2c_exception(hi2c1.ErrorCode);
        printf("I2C Write Error: 0x%08lX at tick %lu\r\n", hi2c1.ErrorCode, HAL_GetTick());
    }
    return status;
}

HAL_StatusTypeDef MB85rc_Bus_Read_Safe(uint16_t DevAddress, uint16_t MemAddress, uint8_t *pData, uint16_t Size) {
    HAL_StatusTypeDef status = MB85rc_Bus_Read(DevAddress, MemAddress, pData, Size);
    if (status != HAL_OK) {
        record_i2c_exception(hi2c1.ErrorCode);
        printf("I2C Read Error: 0x%08lX at tick %lu\r\n", hi2c1.ErrorCode, HAL_GetTick());
    }
    return status;
}

void save_heading_lock_to_eeprom(void) {
	if (heading_lock_enabled) {
		if (osMutexAcquire(I2C1MutexHandle, osWaitForever) == osOK) {
			// Update the structure with current values
			eeStorage.magic_number = EE_MAGIC_NUMBER;
			eeStorage.saved_locked_heading = locked_heading;
			eeStorage.heading_lock_was_active = 1;

			HAL_StatusTypeDef status = MB85rc_Bus_Write_Safe(MB85rc_ADDRESS, 0x0000,
					(uint8_t*) &eeStorage, sizeof(eeStorage_t));

			if (status != HAL_OK) {
				// Turn ON LED to indicate error
				HAL_GPIO_WritePin(GPIOC, GPIO_PIN_13, GPIO_PIN_RESET);

				printf("FRAM Write Failed - Attempting Recovery\r\n");

				// Try recovery: reinitialize I2C
				HAL_I2C_DeInit(&hi2c1);
				HAL_Delay(10);
				MX_I2C1_Init();

				// Optional: Try one more time
				status = MB85rc_Bus_Write_Safe(MB85rc_ADDRESS, 0x0000,
						(uint8_t*) &eeStorage, sizeof(eeStorage_t));
				if (status != HAL_OK) {
					printf("FRAM Write Failed Again - Continuing without save\r\n");
					// Keep LED ON to indicate persistent error
				} else {
					printf("FRAM Write Recovered Successfully\r\n");
					// Turn OFF LED after successful recovery
					HAL_GPIO_WritePin(GPIOC, GPIO_PIN_13, GPIO_PIN_SET);
				}
			}
			osMutexRelease(I2C1MutexHandle);
		}
	}
}

bool restore_heading_lock_from_eeprom(void) {
	bool result = false;
	osMutexAcquire(I2C1MutexHandle, osWaitForever);

	HAL_StatusTypeDef status = MB85rc_Bus_Read_Safe(MB85rc_ADDRESS, 0x0000,
			(uint8_t*) &eeStorage, sizeof(eeStorage_t));

	if (status != HAL_OK) {
		// Turn ON LED to indicate error
		HAL_GPIO_WritePin(GPIOC, GPIO_PIN_13, GPIO_PIN_RESET);

		// Try recovery
		HAL_I2C_DeInit(&hi2c1);
		HAL_Delay(10);
		MX_I2C1_Init();

		// Try again
		status = MB85rc_Bus_Read_Safe(MB85rc_ADDRESS, 0x0000,
				(uint8_t*) &eeStorage, sizeof(eeStorage_t));
		if (status == HAL_OK) {
			printf("FRAM Read Recovered Successfully\r\n");
			// Turn OFF LED after successful recovery
			HAL_GPIO_WritePin(GPIOC, GPIO_PIN_13, GPIO_PIN_SET);
		} else {
			printf("FRAM Read Failed - Using defaults\r\n");
			// Keep LED ON to indicate persistent error
			// Initialize with safe defaults
			eeStorage.magic_number = 0; // Invalid magic number
			eeStorage.saved_locked_heading = 0.0f;
			eeStorage.heading_lock_was_active = 0;
		}
	}

	if (status == HAL_OK && eeStorage.magic_number == EE_MAGIC_NUMBER
			&& eeStorage.heading_lock_was_active) {
		locked_heading = eeStorage.saved_locked_heading;
		result = true;
	}

	osMutexRelease(I2C1MutexHandle);
	return result;
}

// Get the current position of channel 7 (assumed to be used for mode selection)
ch7_position_t get_channel7_position(void) {
	if (!is_sbus_signal_valid()) {
		return CH7_POSITION_UNKNOWN;
	}

	uint16_t ch7_value = sbus_channels[6]; // Channel 7 (index 6)

	// Define positions with dead zones (assuming SBUS range 172-1811)
	// Min: 172-500, Mid: 700-1283, Max: 1511-1811
	if (ch7_value >= 172 && ch7_value <= 500) {
		return CH7_POSITION_MIN;
	} else if (ch7_value >= 700 && ch7_value <= 1283) {
		return CH7_POSITION_MID;
	} else if (ch7_value >= 1511 && ch7_value <= 1811) {
		return CH7_POSITION_MAX;
	}

	return CH7_POSITION_UNKNOWN; // In dead zone or invalid
}

void print_system_status(void) {
    printf("\r\n=== OPTIMIZED SYSTEM STATUS ===\r\n");
    printf("CPU: %lu MHz\r\n", HAL_RCC_GetSysClockFreq() / 1000000);
    printf("AHB: %lu MHz\r\n", HAL_RCC_GetHCLKFreq() / 1000000);
    printf("APB1: %lu MHz\r\n", HAL_RCC_GetPCLK1Freq() / 1000000);
    printf("APB2: %lu MHz\r\n", HAL_RCC_GetPCLK2Freq() / 1000000);

    // For STM32F4, check if caches are enabled differently
    #if defined(SCB_CCR_IC_Msk) && defined(SCB_CCR_DC_Msk)
        printf("I-Cache: %s\r\n", (SCB->CCR & SCB_CCR_IC_Msk) ? "ON" : "OFF");
        printf("D-Cache: %s\r\n", (SCB->CCR & SCB_CCR_DC_Msk) ? "ON" : "OFF");
    #else
        // STM32F4 doesn't have separate I/D cache control in CCR
        printf("Cache: Enabled\r\n");
    #endif

    // FreeRTOS heap status
    if (osKernelGetState() == osKernelRunning) {
        printf("Free Heap: %u bytes\r\n", xPortGetFreeHeapSize());
        printf("Current Task: %s\r\n", osThreadGetName(osThreadGetId()));
    } else {
        printf("FreeRTOS: Not Running\r\n");
    }

    // Timer frequencies - Fixed format specifiers
    uint32_t tim1_freq = HAL_RCC_GetPCLK2Freq() / ((htim1.Init.Prescaler + 1) * (htim1.Init.Period + 1));
    uint32_t tim3_freq = (HAL_RCC_GetPCLK1Freq() * 2) / ((htim3.Init.Prescaler + 1) * (htim3.Init.Period + 1));
    printf("TIM1 PWM: %lu Hz (%lu steps)\r\n", tim1_freq, (unsigned long)(htim1.Init.Period + 1));
    printf("TIM3 PWM: %lu Hz (%lu steps)\r\n", tim3_freq, (unsigned long)(htim3.Init.Period + 1));

    // I2C status
    printf("I2C1: %s\r\n", (hi2c1.State == HAL_I2C_STATE_READY) ? "READY" : "BUSY");

    // SBUS status
    printf("SBUS: %s (Last: %lu ms ago)\r\n",
           sbus_signal_valid ? "VALID" : "INVALID",
           HAL_GetTick() - sbus_last_valid_time);

    // Robot status
    const char *mode_names[] = { "SENSOR", "MOVE", "MOVE_HL" };
    const char *state_names[] = { "IDLE", "RUN" };
    printf("Mode: %s, State: %s\r\n", mode_names[current_mode], state_names[robot_state]);
    printf("Heading Lock: %s\r\n", heading_lock_enabled ? "ENABLED" : "DISABLED");

    printf("=== END STATUS ===\r\n\r\n");
}

/* USER CODE END 0 */

int main(void)
{

  /* USER CODE BEGIN 1 */
	// STM32F4 cache configuration (different from STM32F7/H7)
	#if defined(STM32F4)
	    // Enable prefetch buffer for STM32F4
	    __HAL_FLASH_PREFETCH_BUFFER_ENABLE();

	    // Enable ART accelerator only if available
	    #if defined(__HAL_FLASH_ART_ENABLE)
	        __HAL_FLASH_ART_ENABLE();
	    #endif

	    // Enable instruction cache if available (some STM32F4 variants)
	    #if defined(FLASH_ACR_ICEN)
	        __HAL_FLASH_INSTRUCTION_CACHE_ENABLE();
	    #endif

	    // Enable data cache if available (some STM32F4 variants)
	    #if defined(FLASH_ACR_DCEN)
	        __HAL_FLASH_DATA_CACHE_ENABLE();
	    #endif
	#else
	    // For STM32F7/H7 and other Cortex-M7 devices
	    SCB_EnableICache();
	    SCB_EnableDCache();
	#endif
  /* USER CODE END 1 */

  /* MCU Configuration--------------------------------------------------------*/

  /* Reset of all peripherals, Initializes the Flash interface and the Systick. */
  HAL_Init();

  /* Configure the system clock */
  SystemClock_Config();

  /* Initialize all configured peripherals */
  MX_GPIO_Init();
  MX_DMA_Init();
  MX_I2C1_Init();
  MX_USART2_UART_Init();
  MX_TIM1_Init();
  MX_TIM3_Init();
  MX_IWDG_Init();
  MX_USART1_UART_Init();
  /* USER CODE BEGIN 2 */
	HAL_UART_Receive_DMA(&huart2, sbus_rx_buffer, SBUS_FRAME_SIZE);

	TB6612FNG_Init(); // Initialize TB6612 drivers and PWM

	/* KS
	 EE_Init(&eeStorage, sizeof(eeStorage_t)); // Initialize EEPROM emulation with storage structure
	 */

	char i2c_devices[128];
	//  char display_str[48];

	// Turn ON LED during initialization (PC13 is active LOW)
	HAL_GPIO_WritePin(GPIOC, GPIO_PIN_13, GPIO_PIN_RESET);

	HAL_Delay(BNO085_BOOT_DELAY_MS);

	// Set PC13 high to turn the onboard LED off
	HAL_GPIO_WritePin(GPIOC, GPIO_PIN_13, GPIO_PIN_SET);

	printf("Start I2C BUS Scan\r\n");
	i2c_bus_scan(i2c_devices, sizeof(i2c_devices)); // Scan and store result

	uint8_t chip_id = bno085_read_chip_id();
	if (chip_id == 0xFF) {
		// Optionally display error on OLED
		Error_Handler();
	}

	printf("About to setup BNO085 Compass\r\n");
	bno085_setup();
	//HAL_Delay(100); // Give BNO085 time to boot
	sh2_clearTare(); // Now device uses absolute/magnetic north as reference
	printf("BNO085 Compass setup successful\r\n");

	printf("About to initialize SSD1306 LCD\r\n");
	// Init lcd using one of the stm32HAL i2c typedefs
	if (ssd1306_Init(&hi2c1) != 0) {
		printf("Unable to initialize SSD1306 LCD\r\n");
		Error_Handler();
	}
	printf("SSD1306 Initialized\r\n");

	// Initialize the MB85RC256V EEPROM with the I2C handle
	printf("About to initialize MB85RC256V EEPROM\r\n");
	MB85rc_Init(&hi2c1);
	if (HAL_I2C_IsDeviceReady(&hi2c1, MB85rc_ADDRESS, 3, 100) != HAL_OK) {
		printf("Unable to initialize MB85RC256V EEPROM\r\n");
		// Device not ready, handle error
		Error_Handler();
	} else {
		printf("MB85RC256V EEPROM Device Ready\r\n");
		// FRAM is ready - display status information
		ssd1306_Fill(Black);
		ssd1306_SetCursor(1, 0);
		ssd1306_WriteString("FRAM MB85RC256V", Font_7x10, White);

		// Display FRAM address
		char fram_info[32];
		snprintf(fram_info, sizeof(fram_info), "Addr: 0x%02X", MB85rc_ADDRESS);
		ssd1306_SetCursor(1, 12);
		ssd1306_WriteString(fram_info, Font_7x10, White);
		printf("FRAM MB85RC256V initialized: %s, Status: OK\r\n", fram_info);

		// Display FRAM size (32KB for MB85RC256V)
		ssd1306_SetCursor(1, 24);
		ssd1306_WriteString("Size: 32KB", Font_7x10, White);

		// Display initialization status
		ssd1306_SetCursor(1, 36);
		ssd1306_WriteString("Status: OK", Font_7x10, White);

		ssd1306_UpdateScreen(&hi2c1);
		HAL_IWDG_Refresh(&hiwdg);
		HAL_Delay(2000); // Show FRAM info for 2 seconds
	}

	ssd1306_Fill(Black);
	ssd1306_UpdateScreen(&hi2c1);

	HAL_IWDG_Refresh(&hiwdg); // Refresh watchdog
	HAL_Delay(1000);

	// Write data to local screenbuffer
	ssd1306_SetCursor(1, 0);
	ssd1306_WriteString(APP_VERSION, Font_7x10, White);
	ssd1306_SetCursor(1, 12);
	if (i2c_devices[0] == '\0') {
		printf("No I2C devices found\r\n");
		ssd1306_WriteString("No I2C found", Font_7x10, White);
	} else {
		printf("I2C devices found: %s\r\n", i2c_devices);
		ssd1306_WriteString("I2C:", Font_7x10, White);
		ssd1306_SetCursor(1, 24);
		ssd1306_WriteString(i2c_devices, Font_7x10, White);
	}

	// Copy all data from local screenbuffer to the screen
	ssd1306_UpdateScreen(&hi2c1);

	HAL_IWDG_Refresh(&hiwdg); // Refresh watchdog
	// Delay to see I2C info
	HAL_Delay(2000);

	// Turn OFF LED after successful initialization (PC13 is active LOW)
	HAL_GPIO_WritePin(GPIOC, GPIO_PIN_13, GPIO_PIN_SET);
	printf("System initialization completed - LED turned OFF\r\n");

    // Print system status after initialization
    print_system_status();
  /* USER CODE END 2 */

  /* Init scheduler */
  osKernelInitialize();
  /* Create the mutex(es) */
  /* creation of CompassMutex */
  CompassMutexHandle = osMutexNew(&CompassMutex_attributes);

  /* creation of I2C1Mutex */
  I2C1MutexHandle = osMutexNew(&I2C1Mutex_attributes);

  /* creation of EncoderMutex */
  EncoderMutexHandle = osMutexNew(&EncoderMutex_attributes);

  /* creation of UARTMutex */
  UARTMutexHandle = osMutexNew(&UARTMutex_attributes);

  /* creation of ModeMutex */
  ModeMutexHandle = osMutexNew(&ModeMutex_attributes);

  /* creation of EEPROMMutex */
  EEPROMMutexHandle = osMutexNew(&EEPROMMutex_attributes);

  /* Create the thread(s) */
  /* creation of defaultTask */
  defaultTaskHandle = osThreadNew(StartDefaultTask, NULL, &defaultTask_attributes);

  /* creation of CompassTask */
  CompassTaskHandle = osThreadNew(StartCompassTask, NULL, &CompassTask_attributes);

  /* creation of DisplayTask */
  DisplayTaskHandle = osThreadNew(StartDisplayTask, NULL, &DisplayTask_attributes);

  /* creation of EncoderTask */
  EncoderTaskHandle = osThreadNew(StartEncoderTask, NULL, &EncoderTask_attributes);

  /* Start scheduler */
  osKernelStart();

  /* We should never get here as control is now taken by the scheduler */

  /* Infinite loop */
	while (1) {
		osDelay(1);

	}
}

void SystemClock_Config(void)
{
  RCC_OscInitTypeDef RCC_OscInitStruct = {0};
  RCC_ClkInitTypeDef RCC_ClkInitStruct = {0};

  /** Configure the main internal regulator output voltage
  */
  __HAL_RCC_PWR_CLK_ENABLE();
  __HAL_PWR_VOLTAGESCALING_CONFIG(PWR_REGULATOR_VOLTAGE_SCALE1);

  /** Initializes the RCC Oscillators according to the specified parameters
  * in the RCC_OscInitTypeDef structure.
  */
  RCC_OscInitStruct.OscillatorType = RCC_OSCILLATORTYPE_LSI|RCC_OSCILLATORTYPE_HSE;
  RCC_OscInitStruct.HSEState = RCC_HSE_ON;
  RCC_OscInitStruct.LSIState = RCC_LSI_ON;
  RCC_OscInitStruct.PLL.PLLState = RCC_PLL_ON;
  RCC_OscInitStruct.PLL.PLLSource = RCC_PLLSOURCE_HSE;
  RCC_OscInitStruct.PLL.PLLM = 25;
  RCC_OscInitStruct.PLL.PLLN = 200;
  RCC_OscInitStruct.PLL.PLLP = RCC_PLLP_DIV2;
  RCC_OscInitStruct.PLL.PLLQ = 4;
  if (HAL_RCC_OscConfig(&RCC_OscInitStruct) != HAL_OK)
  {
    Error_Handler();
  }

  /** Initializes the CPU, AHB and APB buses clocks
  */
  RCC_ClkInitStruct.ClockType = RCC_CLOCKTYPE_HCLK|RCC_CLOCKTYPE_SYSCLK
                              |RCC_CLOCKTYPE_PCLK1|RCC_CLOCKTYPE_PCLK2;
  RCC_ClkInitStruct.SYSCLKSource = RCC_SYSCLKSOURCE_PLLCLK;
  RCC_ClkInitStruct.AHBCLKDivider = RCC_SYSCLK_DIV1;
  RCC_ClkInitStruct.APB1CLKDivider = RCC_HCLK_DIV2;
  RCC_ClkInitStruct.APB2CLKDivider = RCC_HCLK_DIV1;

  if (HAL_RCC_ClockConfig(&RCC_ClkInitStruct, FLASH_LATENCY_3) != HAL_OK)
  {
    Error_Handler();
  }
}

static void MX_I2C1_Init(void)
{

  hi2c1.Instance = I2C1;
  hi2c1.Init.ClockSpeed = 400000;
  hi2c1.Init.DutyCycle = I2C_DUTYCYCLE_16_9;
  hi2c1.Init.OwnAddress1 = 0;
  hi2c1.Init.AddressingMode = I2C_ADDRESSINGMODE_7BIT;
  hi2c1.Init.DualAddressMode = I2C_DUALADDRESS_DISABLE;
  hi2c1.Init.OwnAddress2 = 0;
  hi2c1.Init.GeneralCallMode = I2C_GENERALCALL_DISABLE;
  hi2c1.Init.NoStretchMode = I2C_NOSTRETCH_DISABLE;
  if (HAL_I2C_Init(&hi2c1) != HAL_OK)
  {
    Error_Handler();
  }

}

static void MX_IWDG_Init(void)
{

  hiwdg.Instance = IWDG;
  hiwdg.Init.Prescaler = IWDG_PRESCALER_64;
  hiwdg.Init.Reload = 3125;
  if (HAL_IWDG_Init(&hiwdg) != HAL_OK)
  {
    Error_Handler();
  }

}

static void MX_TIM1_Init(void)
{

  TIM_MasterConfigTypeDef sMasterConfig = {0};
  TIM_OC_InitTypeDef sConfigOC = {0};
  TIM_BreakDeadTimeConfigTypeDef sBreakDeadTimeConfig = {0};

  htim1.Instance = TIM1;
  htim1.Init.Prescaler = 99;
  htim1.Init.CounterMode = TIM_COUNTERMODE_UP;
  htim1.Init.Period = 49;
  htim1.Init.ClockDivision = TIM_CLOCKDIVISION_DIV1;
  htim1.Init.RepetitionCounter = 0;
  htim1.Init.AutoReloadPreload = TIM_AUTORELOAD_PRELOAD_DISABLE;
  if (HAL_TIM_PWM_Init(&htim1) != HAL_OK)
  {
    Error_Handler();
  }
  sMasterConfig.MasterOutputTrigger = TIM_TRGO_RESET;
  sMasterConfig.MasterSlaveMode = TIM_MASTERSLAVEMODE_DISABLE;
  if (HAL_TIMEx_MasterConfigSynchronization(&htim1, &sMasterConfig) != HAL_OK)
  {
    Error_Handler();
  }
  sConfigOC.OCMode = TIM_OCMODE_PWM1;
  sConfigOC.Pulse = 0;
  sConfigOC.OCPolarity = TIM_OCPOLARITY_HIGH;
  sConfigOC.OCNPolarity = TIM_OCNPOLARITY_HIGH;
  sConfigOC.OCFastMode = TIM_OCFAST_DISABLE;
  sConfigOC.OCIdleState = TIM_OCIDLESTATE_RESET;
  sConfigOC.OCNIdleState = TIM_OCNIDLESTATE_RESET;
  if (HAL_TIM_PWM_ConfigChannel(&htim1, &sConfigOC, TIM_CHANNEL_1) != HAL_OK)
  {
    Error_Handler();
  }
  if (HAL_TIM_PWM_ConfigChannel(&htim1, &sConfigOC, TIM_CHANNEL_2) != HAL_OK)
  {
    Error_Handler();
  }
  if (HAL_TIM_PWM_ConfigChannel(&htim1, &sConfigOC, TIM_CHANNEL_4) != HAL_OK)
  {
    Error_Handler();
  }
  sBreakDeadTimeConfig.OffStateRunMode = TIM_OSSR_DISABLE;
  sBreakDeadTimeConfig.OffStateIDLEMode = TIM_OSSI_DISABLE;
  sBreakDeadTimeConfig.LockLevel = TIM_LOCKLEVEL_OFF;
  sBreakDeadTimeConfig.DeadTime = 0;
  sBreakDeadTimeConfig.BreakState = TIM_BREAK_DISABLE;
  sBreakDeadTimeConfig.BreakPolarity = TIM_BREAKPOLARITY_HIGH;
  sBreakDeadTimeConfig.AutomaticOutput = TIM_AUTOMATICOUTPUT_DISABLE;
  if (HAL_TIMEx_ConfigBreakDeadTime(&htim1, &sBreakDeadTimeConfig) != HAL_OK)
  {
    Error_Handler();
  }
  HAL_TIM_MspPostInit(&htim1);

}

static void MX_TIM3_Init(void)
{

  TIM_MasterConfigTypeDef sMasterConfig = {0};
  TIM_OC_InitTypeDef sConfigOC = {0};

  htim3.Instance = TIM3;
  htim3.Init.Prescaler = 99;
  htim3.Init.CounterMode = TIM_COUNTERMODE_UP;
  htim3.Init.Period = 49;
  htim3.Init.ClockDivision = TIM_CLOCKDIVISION_DIV1;
  htim3.Init.AutoReloadPreload = TIM_AUTORELOAD_PRELOAD_DISABLE;
  if (HAL_TIM_PWM_Init(&htim3) != HAL_OK)
  {
    Error_Handler();
  }
  sMasterConfig.MasterOutputTrigger = TIM_TRGO_RESET;
  sMasterConfig.MasterSlaveMode = TIM_MASTERSLAVEMODE_DISABLE;
  if (HAL_TIMEx_MasterConfigSynchronization(&htim3, &sMasterConfig) != HAL_OK)
  {
    Error_Handler();
  }
  sConfigOC.OCMode = TIM_OCMODE_PWM1;
  sConfigOC.Pulse = 0;
  sConfigOC.OCPolarity = TIM_OCPOLARITY_HIGH;
  sConfigOC.OCFastMode = TIM_OCFAST_DISABLE;
  if (HAL_TIM_PWM_ConfigChannel(&htim3, &sConfigOC, TIM_CHANNEL_2) != HAL_OK)
  {
    Error_Handler();
  }
  HAL_TIM_MspPostInit(&htim3);

}

static void MX_USART1_UART_Init(void)
{

  huart1.Instance = USART1;
  huart1.Init.BaudRate = 115200;
  huart1.Init.WordLength = UART_WORDLENGTH_8B;
  huart1.Init.StopBits = UART_STOPBITS_1;
  huart1.Init.Parity = UART_PARITY_NONE;
  huart1.Init.Mode = UART_MODE_TX;
  huart1.Init.HwFlowCtl = UART_HWCONTROL_NONE;
  huart1.Init.OverSampling = UART_OVERSAMPLING_16;
  if (HAL_UART_Init(&huart1) != HAL_OK)
  {
    Error_Handler();
  }

}

static void MX_USART2_UART_Init(void)
{

  huart2.Instance = USART2;
  huart2.Init.BaudRate = 100000;
  huart2.Init.WordLength = UART_WORDLENGTH_9B;
  huart2.Init.StopBits = UART_STOPBITS_2;
  huart2.Init.Parity = UART_PARITY_EVEN;
  huart2.Init.Mode = UART_MODE_RX;
  huart2.Init.HwFlowCtl = UART_HWCONTROL_NONE;
  huart2.Init.OverSampling = UART_OVERSAMPLING_16;
  if (HAL_UART_Init(&huart2) != HAL_OK)
  {
    Error_Handler();
  }

}

static void MX_DMA_Init(void)
{

  /* DMA controller clock enable */
  __HAL_RCC_DMA1_CLK_ENABLE();

  /* DMA interrupt init */
  /* DMA1_Stream5_IRQn interrupt configuration */
  HAL_NVIC_SetPriority(DMA1_Stream5_IRQn, 5, 0);
  HAL_NVIC_EnableIRQ(DMA1_Stream5_IRQn);

}

static void MX_GPIO_Init(void)
{
  GPIO_InitTypeDef GPIO_InitStruct = {0};

  /* GPIO Ports Clock Enable */
  __HAL_RCC_GPIOC_CLK_ENABLE();
  __HAL_RCC_GPIOH_CLK_ENABLE();
  __HAL_RCC_GPIOA_CLK_ENABLE();
  __HAL_RCC_GPIOB_CLK_ENABLE();

  /*Configure GPIO pin Output Level */
  HAL_GPIO_WritePin(GPIOC, GPIO_PIN_13, GPIO_PIN_RESET);

  /*Configure GPIO pin Output Level */
  HAL_GPIO_WritePin(GPIOA, Motor_1A_IN1_Pin|Motor_1A_IN2_Pin, GPIO_PIN_RESET);

  /*Configure GPIO pin Output Level */
  HAL_GPIO_WritePin(GPIOB, Motor_2A_IN1_Pin|Motor_2A_IN2_Pin|Motor_1B_IN2_Pin|TB6612__1_STBY_Pin
                          |TB6612__2_STBY_Pin|Motor_2B_IN1_Pin|Motor_2B_IN2_Pin|Motor_1B_IN1_Pin, GPIO_PIN_RESET);

  /*Configure GPIO pin : PC13 */
  GPIO_InitStruct.Pin = GPIO_PIN_13;
  GPIO_InitStruct.Mode = GPIO_MODE_OUTPUT_PP;
  GPIO_InitStruct.Pull = GPIO_NOPULL;
  GPIO_InitStruct.Speed = GPIO_SPEED_FREQ_LOW;
  HAL_GPIO_Init(GPIOC, &GPIO_InitStruct);

  /*Configure GPIO pins : Motor_1A_IN1_Pin Motor_1A_IN2_Pin */
  GPIO_InitStruct.Pin = Motor_1A_IN1_Pin|Motor_1A_IN2_Pin;
  GPIO_InitStruct.Mode = GPIO_MODE_OUTPUT_PP;
  GPIO_InitStruct.Pull = GPIO_NOPULL;
  GPIO_InitStruct.Speed = GPIO_SPEED_FREQ_LOW;
  HAL_GPIO_Init(GPIOA, &GPIO_InitStruct);

  /*Configure GPIO pin : INT_for_CLK___SNP00128_Pin */
  GPIO_InitStruct.Pin = INT_for_CLK___SNP00128_Pin;
  GPIO_InitStruct.Mode = GPIO_MODE_IT_RISING_FALLING;
  GPIO_InitStruct.Pull = GPIO_PULLUP;
  HAL_GPIO_Init(INT_for_CLK___SNP00128_GPIO_Port, &GPIO_InitStruct);

  /*Configure GPIO pin : for_DT___SNP00128_Pin */
  GPIO_InitStruct.Pin = for_DT___SNP00128_Pin;
  GPIO_InitStruct.Mode = GPIO_MODE_INPUT;
  GPIO_InitStruct.Pull = GPIO_PULLUP;
  HAL_GPIO_Init(for_DT___SNP00128_GPIO_Port, &GPIO_InitStruct);

  /*Configure GPIO pin : INT_for_SW___SNP00128_Pin */
  GPIO_InitStruct.Pin = INT_for_SW___SNP00128_Pin;
  GPIO_InitStruct.Mode = GPIO_MODE_IT_FALLING;
  GPIO_InitStruct.Pull = GPIO_PULLUP;
  HAL_GPIO_Init(INT_for_SW___SNP00128_GPIO_Port, &GPIO_InitStruct);

  /*Configure GPIO pins : Motor_2A_IN1_Pin Motor_2A_IN2_Pin Motor_1B_IN2_Pin TB6612__1_STBY_Pin
                           TB6612__2_STBY_Pin Motor_2B_IN1_Pin Motor_2B_IN2_Pin Motor_1B_IN1_Pin */
  GPIO_InitStruct.Pin = Motor_2A_IN1_Pin|Motor_2A_IN2_Pin|Motor_1B_IN2_Pin|TB6612__1_STBY_Pin
                          |TB6612__2_STBY_Pin|Motor_2B_IN1_Pin|Motor_2B_IN2_Pin|Motor_1B_IN1_Pin;
  GPIO_InitStruct.Mode = GPIO_MODE_OUTPUT_PP;
  GPIO_InitStruct.Pull = GPIO_NOPULL;
  GPIO_InitStruct.Speed = GPIO_SPEED_FREQ_LOW;
  HAL_GPIO_Init(GPIOB, &GPIO_InitStruct);

  /*Configure GPIO pin : INT_for_BNO085_Pin */
  GPIO_InitStruct.Pin = INT_for_BNO085_Pin;
  GPIO_InitStruct.Mode = GPIO_MODE_IT_FALLING;
  GPIO_InitStruct.Pull = GPIO_NOPULL;
  HAL_GPIO_Init(INT_for_BNO085_GPIO_Port, &GPIO_InitStruct);

  /* EXTI interrupt init*/
  HAL_NVIC_SetPriority(EXTI4_IRQn, 5, 0);
  HAL_NVIC_EnableIRQ(EXTI4_IRQn);

  HAL_NVIC_SetPriority(EXTI9_5_IRQn, 5, 0);
  HAL_NVIC_EnableIRQ(EXTI9_5_IRQn);

}

/* USER CODE BEGIN 4 */
// EXTI Callback for INT pin (e.g., PA0 for EXTI0)
void HAL_GPIO_EXTI_Callback(uint16_t GPIO_Pin) {
	uint32_t now = HAL_GetTick();

	// BNO085 INT (PA8)
	if (GPIO_Pin == GPIO_PIN_8) {
		bno085_int_flag = 1;
	}
	if (GPIO_Pin == ENC_CLK_Pin) {
		if (HAL_GPIO_ReadPin(ENC_CLK_GPIO_Port, ENC_CLK_Pin)
				== GPIO_PIN_RESET) {
			if (now - last_clk_tick > ENCODER_DEBOUNCE_MS) {
				last_clk_tick = now;
				osMutexAcquire(EncoderMutexHandle, 0);
				if (HAL_GPIO_ReadPin(ENC_DT_GPIO_Port, ENC_DT_Pin)
						== GPIO_PIN_SET)
					encoder_count++;
				else
					encoder_count--;
				osMutexRelease(EncoderMutexHandle);
			}
		}
	}

	if (GPIO_Pin == ENC_SW_Pin) {
		GPIO_PinState clk_state = HAL_GPIO_ReadPin(ENC_CLK_GPIO_Port,
				ENC_CLK_Pin);
		GPIO_PinState dt_state = HAL_GPIO_ReadPin(ENC_DT_GPIO_Port,
				ENC_DT_Pin);
		GPIO_PinState sw_state = HAL_GPIO_ReadPin(ENC_SW_GPIO_Port,
				ENC_SW_Pin);
		// Only count if button is actually pressed (logic low) and both CLK and DT are high
		// Note: When turn rotary knob left/right, SW pin is always pulled low together with CLK and DT pins.
		if (sw_state == GPIO_PIN_RESET) {
			if (dt_state == GPIO_PIN_SET) {
				if (clk_state == GPIO_PIN_SET) {
					// Ignore SW if just rotated (within 10 ms of last CLK)
					if ((now - last_clk_tick) > CLK_SW_DEBOUNCE_MS) {
						if (now - last_sw_tick > BUTTON_DEBOUNCE_MS) {
							last_sw_tick = now;
							osMutexAcquire(EncoderMutexHandle, 0);
							encoder_button_pressed = 1;
							encoder_sw_count++; // Increment counter on each debounced press
							osMutexRelease(EncoderMutexHandle);
						}
					}
				}
			}
		}
	}
}

void HAL_UART_RxCpltCallback(UART_HandleTypeDef *huart) {
	if (huart->Instance == USART2) {
		// Validate SBUS frame start and end bytes
		if (sbus_rx_buffer[0] == 0x0F && sbus_rx_buffer[24] == 0x00) {
			// Valid SBUS frame received
			sbus_last_valid_time = HAL_GetTick();
			sbus_signal_valid = 1;

			// Unpack all 16 channels
			for (int ch = 0; ch < 16; ch++) {
				int byte_idx = 1 + (ch * 11) / 8;
				int bit_idx = (ch * 11) % 8;
				uint16_t value = (sbus_rx_buffer[byte_idx]
												 | (sbus_rx_buffer[byte_idx + 1] << 8)
												 | (sbus_rx_buffer[byte_idx + 2] << 16));
				value = (value >> bit_idx) & 0x07FF;

				// Additional range validation
				if (value >= 172 && value <= 1811) {
					sbus_channels[ch] = value;
				}
			 }
		} else {
			// Invalid frame - don't update sbus_signal_valid or channels
		}
		// DO NOT restart DMA - Circular mode handles this automatically
	}
}

void HAL_UART_ErrorCallback(UART_HandleTypeDef *huart) {
	if (huart->Instance == USART2) {
		// Turn ON LED to indicate SBUS error
		HAL_GPIO_WritePin(GPIOC, GPIO_PIN_13, GPIO_PIN_RESET);

		// Mark SBUS as invalid on UART error
		sbus_signal_valid = 0;

		// Stop all motors immediately for safety
		stop_all_motors_3wheel();

		// Store error information
		osMutexAcquire(UARTMutexHandle, osWaitForever);
		uart2_error_code = huart->ErrorCode;
		uart2_error_flag = 1;
		osMutexRelease(UARTMutexHandle);

		// Set flag for recovery in main task context
		sbus_recovery_requested = 1;
	}
}

/* USER CODE END 4 */

void StartDefaultTask(void *argument)
{
  /* USER CODE BEGIN 5 */
	static uint32_t last_perf_check = 0;
	static ch7_position_t last_ch7_position = CH7_POSITION_UNKNOWN;
	static uint32_t ch7_stable_time = 0;
	const uint32_t CH7_DEBOUNCE_MS = 100; // Debounce time for channel 7
	static uint8_t sbus_was_in_error = 0; // Track SBUS error state

	// Performance monitoring variables
	static uint32_t loop_count = 0;
	static uint32_t max_loop_time = 0;
	static uint32_t avg_loop_time = 0;

	// --- SBUS recovery flag ---
	extern volatile uint8_t sbus_recovery_requested; // Declare if not already global

	/* Infinite loop */
	for (;;) {
		uint32_t loop_start = HAL_GetTick();
		robot_mode_t mode;
		robot_state_t state;
		uint8_t mode_changed = 0;
		uint8_t state_changed = 0;
		uint8_t sbus_valid = 0;
		float current_compass_heading = 0.0f;
		float current_robot_front = 0.0f;

		// --- SBUS Recovery Logic ---
		if (sbus_recovery_requested) {
			sbus_recovery_requested = 0;
			// Perform recovery attempts (non-blocking, watchdog-friendly)
			for (int attempt = 0; attempt < SBUS_MAX_RECOVERY_ATTEMPTS;
					attempt++) {
				HAL_UART_AbortReceive(&huart2);
				MX_USART2_UART_Init();
				HAL_UART_Receive_DMA(&huart2, sbus_rx_buffer, SBUS_FRAME_SIZE);
				HAL_IWDG_Refresh(&hiwdg); // Refresh watchdog during recovery
				osDelay(10); // Give hardware time to settle
				// Optionally check if recovery succeeded and break if so
			}
		}

		// Check SBUS signal validity
		sbus_valid = is_sbus_signal_valid();

		// Handle SBUS recovery LED indication
		if (sbus_valid && sbus_was_in_error) {
			// SBUS recovered - turn OFF LED
			HAL_GPIO_WritePin(GPIOC, GPIO_PIN_13, GPIO_PIN_SET);
			printf("SBUS recovered - LED turned OFF\r\n");
			sbus_was_in_error = 0;
		} else if (!sbus_valid && !sbus_was_in_error) {
			// SBUS lost - turn ON LED
			HAL_GPIO_WritePin(GPIOC, GPIO_PIN_13, GPIO_PIN_RESET);
			printf("SBUS lost - LED turned ON\r\n");
			sbus_was_in_error = 1;
		}

		// Get current compass heading
		osMutexAcquire(CompassMutexHandle, osWaitForever);
		current_compass_heading = compass_heading_deg;
		osMutexRelease(CompassMutexHandle);

		// Convert to robot front direction
		current_robot_front = compass_to_robot_front(current_compass_heading);

		// Check for mode/state changes
		osMutexAcquire(ModeMutexHandle, osWaitForever);
		mode = current_mode;
		state = robot_state;
		if (mode_change_request) {
			mode_change_request = 0;
			mode_changed = 1;
		}
		if (state_toggle_request) {
			state_toggle_request = 0;
			state_changed = 1;
		}
		osMutexRelease(ModeMutexHandle);

		// ENHANCED: Check Channel 7 for automatic mode control
		if (sbus_valid) {
			ch7_position_t current_ch7 = get_channel7_position();
			uint32_t now = HAL_GetTick();

			// Debounce Channel 7 changes
			if (current_ch7 != last_ch7_position
					&& current_ch7 != CH7_POSITION_UNKNOWN) {
				if (ch7_stable_time == 0) {
					ch7_stable_time = now; // Start debounce timer
				} else if ((now - ch7_stable_time) >= CH7_DEBOUNCE_MS) {
					// Channel 7 position has been stable for debounce time
					robot_mode_t target_mode;
					robot_state_t target_state;

					switch (current_ch7) {
					case CH7_POSITION_MIN:
						target_mode = MODE_DISPLAY_SENSORS;
						target_state = STATE_IDLE;
						break;
					case CH7_POSITION_MID:
						target_mode = MODE_MOVEMENT;
						target_state = STATE_RUNNING;
						break;
					case CH7_POSITION_MAX:
						target_mode = MODE_MOVEMENT_HL;
						target_state = STATE_RUNNING;
						break;
					default:
						target_mode = mode; // No change
						target_state = state;
						break;
					}

					// Apply changes if different from current
					osMutexAcquire(ModeMutexHandle, osWaitForever);
					if (target_mode != current_mode
							|| target_state != robot_state) {
						current_mode = target_mode;
						selected_mode = target_mode; // Keep encoder selection in sync
						robot_state = target_state;
						mode_change_request = 1;
						state_toggle_request = 1;
						mode_changed = 1;
						state_changed = 1;
					}
					osMutexRelease(ModeMutexHandle);

					last_ch7_position = current_ch7;
					ch7_stable_time = 0; // Reset debounce timer
				}
			} else if (current_ch7 == last_ch7_position) {
				ch7_stable_time = 0; // Reset debounce if position unchanged
			}
		} else {
			// SBUS invalid - reset Channel 7 tracking
			last_ch7_position = CH7_POSITION_UNKNOWN;
			ch7_stable_time = 0;
		}

		// Handle mode changes
		if (mode_changed) {
			// Stop all motors when changing modes
			stop_all_motors_3wheel();
			// Disable heading lock when changing modes
			disable_heading_lock();
			// Reset recovery state
			sbus_was_lost = 0;
			heading_lock_was_enabled = 0;
		}

		// Handle state changes
		if (state_changed) {
			if (state == STATE_IDLE) {
				// Stop all motors when going to idle
				stop_all_motors_3wheel();
				// Disable heading lock when going to idle
				disable_heading_lock();
				// Reset recovery state
				sbus_was_lost = 0;
				heading_lock_was_enabled = 0;
			} else if (state == STATE_RUNNING && mode == MODE_MOVEMENT_HL) { // UPDATED
				// Enable heading lock when starting movement mode with heading lock
				// Use current compass heading (function will convert to robot front)
				set_heading_lock(current_compass_heading);
				// Reset recovery state for new session
				sbus_was_lost = 0;
				heading_lock_was_enabled = 1;
			}
		}

		// ENHANCED SBUS RECOVERY LOGIC
		if (mode == MODE_MOVEMENT || mode == MODE_MOVEMENT_HL) { // UPDATED
			if (sbus_valid) {
				// SBUS signal is valid

				// Check if we just recovered from SBUS loss
				if (sbus_was_lost && mode == MODE_MOVEMENT_HL
						&& state == STATE_RUNNING) {
					if (heading_lock_was_enabled) {
						// Try to restore from EEPROM first
						if (restore_heading_lock_from_eeprom()) {
							heading_lock_enabled = 1;
							reset_heading_pid();
						} else {
							// Fallback to current heading
							set_heading_lock(current_compass_heading);
						}
					}
					sbus_was_lost = 0;
				}

				// Updated SBUS channel mapping:
				// Channel 2 (index 1): Left/Right (X-axis)
				// Channel 5 (index 4): Forward/Backward (Y-axis)
				// Channel 4 (index 3): Rotation (Z-axis)
				int16_t x = sbus_to_percentage(sbus_channels[1]); // Channel 2: Left/Right
				int16_t y = sbus_to_percentage(sbus_channels[4]); // Channel 5: Forward/Backward
				int16_t rot = sbus_to_percentage(sbus_channels[3]); // Channel 4: Rotation

				// Calculate heading correction if heading lock is enabled
				float heading_correction = 0.0f;
				if (heading_lock_enabled && mode == MODE_MOVEMENT_HL) { // UPDATED
					heading_correction = calculate_heading_pid_simplified(
							locked_heading, current_robot_front);
				}

				// Calculate individual motor speeds for 3-wheel omnidirectional
				int16_t lf, rf, bk;
				if (heading_lock_enabled && mode == MODE_MOVEMENT_HL) { // UPDATED
					calculate_omni_motor_speeds_with_heading(x, y, rot,
							heading_correction, &lf, &rf, &bk);
				} else {
					calculate_omni_motor_speeds(x, y, rot, &lf, &rf, &bk);
				}

				// Update shared variables
				joystick_x = x;
				joystick_y = y;
				joystick_rotation = rot;
				motor_left_front = lf;   // Motor 1B
				motor_right_front = rf;  // Motor 1A
				motor_back = bk;         // Motor 2A

				// Apply to actual motors for both movement modes when running
				if ((mode == MODE_MOVEMENT || mode == MODE_MOVEMENT_HL)
						&& state == STATE_RUNNING) { // UPDATED
					apply_motor_speeds_3wheel(lf, rf, bk);
				}
			} else {
				// SBUS signal lost

				// Remember heading lock state before disabling it
				if (!sbus_was_lost) {
					// First time detecting SBUS loss
					heading_lock_was_enabled = heading_lock_enabled;
					sbus_was_lost = 1;
				}

				// Stop all motors immediately for safety
				stop_all_motors_3wheel();
				// Temporarily disable heading lock (but remember its state)
				disable_heading_lock();

				// Reset joystick values to indicate no signal
				joystick_x = 0;
				joystick_y = 0;
				joystick_rotation = 0;
				motor_left_front = 0;
				motor_right_front = 0;
				motor_back = 0;
			}
		}

		// Performance monitoring (every 5 seconds)
		uint32_t loop_end = HAL_GetTick();
		uint32_t loop_time = loop_end - loop_start;

		loop_count++;
		if (loop_time > max_loop_time) max_loop_time = loop_time;
		avg_loop_time = (avg_loop_time * (loop_count - 1) + loop_time) / loop_count;

		if ((loop_end - last_perf_check) >= 5000) {
			last_perf_check = loop_end;
			printf("Perf: Loop=%lums, Max=%lums, Avg=%lums, Heap=%u\r\n",
					loop_time, max_loop_time, avg_loop_time, xPortGetFreeHeapSize());
			max_loop_time = 0;  // Reset max
			loop_count = 0;     // Reset counter
			avg_loop_time = 0;  // Reset average
		}

		HAL_IWDG_Refresh(&hiwdg); // Refresh watchdog

		osDelay(50); // Update at 20Hz
	}
  /* USER CODE END 5 */
}

void StartCompassTask(void *argument)
{
  /* USER CODE BEGIN StartCompassTask */
	/* Infinite loop */
	for (;;) {
		if (bno085_int_flag) {
			bno085_int_flag = 0;
			sh2_service();
		}
		osDelay(10);
	}
  /* USER CODE END StartCompassTask */
}

void StartDisplayTask(void *argument)
{
  /* USER CODE BEGIN StartDisplayTask */
	char display_str[48];
	const char *mode_names[] = { "SENSOR", "MOVE", "MOVE_HL" }; // UPDATED NAMES
	const char *state_names[] = { "IDLE", "RUN" };
	/* Infinite loop */
	for (;;) {
		robot_mode_t mode;
		robot_mode_t sel_mode;
		robot_state_t state;
		float heading;
		int32_t sw_count, enc_count;
		uint8_t show_uart_error = 0;
		uint8_t sbus_valid = 0;
		uint32_t error_code = 0;

		// Check SBUS signal validity
		sbus_valid = is_sbus_signal_valid();

		// Check for UART error under mutex
		osMutexAcquire(UARTMutexHandle, osWaitForever);
		if (uart2_error_flag) {
			show_uart_error = 1;
			error_code = uart2_error_code;
			uart2_error_flag = 0; // Clear after displaying
		}
		osMutexRelease(UARTMutexHandle);

		if (show_uart_error) {
			char err_str[32];
			// Show more detailed error information
			snprintf(err_str, sizeof(err_str), "UART Err: 0x%lX A:%d",
					error_code, sbus_recovery_attempts);
			ssd1306_Fill(Black);
			ssd1306_SetCursor(1, 0);
			ssd1306_WriteString(err_str, Font_7x10, White);

			// Show recovery status
			snprintf(err_str, sizeof(err_str), "Recovery: %s",
					(sbus_recovery_attempts < SBUS_MAX_RECOVERY_ATTEMPTS) ?
							"TRYING" : "FAILED");
			ssd1306_SetCursor(1, 12);
			ssd1306_WriteString(err_str, Font_7x10, White);

			ssd1306_UpdateScreen(&hi2c1);
			osDelay(2000); // Show error for 2s
			continue;
		}

		// Get current mode, selected mode, and state
		osMutexAcquire(ModeMutexHandle, osWaitForever);
		mode = current_mode;
		sel_mode = selected_mode;
		state = robot_state;
		osMutexRelease(ModeMutexHandle);

		// Get compass heading
		osMutexAcquire(CompassMutexHandle, osWaitForever);
		heading = compass_heading_deg;
		osMutexRelease(CompassMutexHandle);

		// Get encoder data
		osMutexAcquire(EncoderMutexHandle, osWaitForever);
		sw_count = encoder_sw_count;
		enc_count = encoder_count;
		osMutexRelease(EncoderMutexHandle);

		ssd1306_Fill(Black);

		// Line 1: Show selected mode with indicator if different from current
		// Add SBUS status, recovery status, and heading lock indicator
		if (sel_mode == mode) {
			// Current mode - show with state, SBUS status, recovery status, and heading lock
			char sbus_status = sbus_valid ? 'S' : '!';
			char recovery_status = sbus_was_lost ? 'R' : ' '; // R = recovering
			char heading_status =
					(heading_lock_enabled && mode == MODE_MOVEMENT_HL) ?
							'H' : ' '; // UPDATED

			snprintf(display_str, sizeof(display_str), "%s %s %c%c%c",
					mode_names[mode], state_names[state], sbus_status,
					recovery_status, heading_status);
		} else {
			// Selected mode (different from current) - show with arrow indicator
			char sbus_status = sbus_valid ? 'S' : '!';
			char recovery_status = sbus_was_lost ? 'R' : ' ';
			char heading_status =
					(heading_lock_enabled && mode == MODE_MOVEMENT_HL) ?
							'H' : ' '; // UPDATED

			snprintf(display_str, sizeof(display_str), ">%s< %s %c%c%c",
					mode_names[sel_mode], state_names[state], sbus_status,
					recovery_status, heading_status);
		}
		ssd1306_SetCursor(1, 0);
		ssd1306_WriteString(display_str, Font_7x10, White);

		// Display content based on current active mode (not selected mode)
		switch (mode) {
		case MODE_DISPLAY_SENSORS:
			// Line 2: Show both compass and robot front headings
			float robot_front = compass_to_robot_front(heading);
			snprintf(display_str, sizeof(display_str), "C:%.0f R:%.0f deg",
					heading, robot_front);
			ssd1306_SetCursor(1, 12);
			ssd1306_WriteString(display_str, Font_7x10, White);

			// Line 3: Encoder data and Channel 7 position
			const char *ch7_names[] = { "MIN", "MID", "MAX", "???" };
			ch7_position_t ch7_pos =
					sbus_valid ? get_channel7_position() : CH7_POSITION_UNKNOWN;
			snprintf(display_str, sizeof(display_str), "SW:%ld ENC:%ld CH7:%s",
					(long) sw_count, (long) enc_count, ch7_names[ch7_pos]);
			ssd1306_SetCursor(1, 24);
			ssd1306_WriteString(display_str, Font_7x10, White);

			// Line 4: SBUS channels including Channel 7 raw value
			if (sbus_valid) {
				int16_t ch2_pct = sbus_to_percentage(sbus_channels[1]);
				int16_t ch5_pct = sbus_to_percentage(sbus_channels[4]);
				int16_t ch4_pct = sbus_to_percentage(sbus_channels[3]);
				snprintf(display_str, sizeof(display_str), "2:%3d 5:%3d 4:%3d",
						ch2_pct, ch5_pct, ch4_pct);
			} else {
				snprintf(display_str, sizeof(display_str), "SBUS SIGNAL LOST");
			}
			ssd1306_SetCursor(1, 36);
			ssd1306_WriteString(display_str, Font_7x10, White);

			// Line 5: FRAM status with I2C error tracking
			if (exception_info.i2c_error_count > 0) {
				uint32_t time_since_i2c_error = HAL_GetTick() - exception_info.last_exception_time;
				if (time_since_i2c_error < 30000) { // Show I2C error for 30 seconds
					snprintf(display_str, sizeof(display_str), "I2C Err:0x%lX #%lu",
							exception_info.last_i2c_error, exception_info.i2c_error_count);
				} else {
					// Check current FRAM status
					if (HAL_I2C_IsDeviceReady(&hi2c1, MB85rc_ADDRESS, 1, 50) == HAL_OK) {
						snprintf(display_str, sizeof(display_str), "FRAM: OK");
					} else {
						snprintf(display_str, sizeof(display_str), "FRAM: ERR");
					}
				}
			} else {
				// No I2C errors - check current FRAM status
				if (HAL_I2C_IsDeviceReady(&hi2c1, MB85rc_ADDRESS, 1, 50) == HAL_OK) {
					snprintf(display_str, sizeof(display_str), "FRAM: OK");
				} else {
					snprintf(display_str, sizeof(display_str), "FRAM: ERR");
				}
			}
			ssd1306_SetCursor(1, 48);
			ssd1306_WriteString(display_str, Font_7x10, White);
			break;

		case MODE_MOVEMENT:        // UPDATED - was MODE_MOVEMENT_SIMULATOR
		case MODE_MOVEMENT_HL:     // UPDATED - was MODE_MOVEMENT
			if (sbus_valid) {
				// Line 2: Joystick input values (LR=Left/Right, FB=Forward/Backward, R=Rotation)
				snprintf(display_str, sizeof(display_str),
						"LR:%3d FB:%3d R:%3d", joystick_x, joystick_y,
						joystick_rotation);
				ssd1306_SetCursor(1, 12);
				ssd1306_WriteString(display_str, Font_7x10, White);

				// Line 3: Show heading lock info with oscillation detection
				if (heading_lock_enabled && mode == MODE_MOVEMENT_HL) { // UPDATED
					float current_robot_front = compass_to_robot_front(heading);

					// Enhanced status indicators
					char status_char = ' ';
					if (oscillation_detected) {
						status_char = '~'; // Oscillation detected
					} else if (overshoot_detected) {
						status_char = 'O'; // Overshoot detected
					} else if (fabs(heading_error) > 2.0f) { // Reduced threshold
						status_char = (heading_pid_output > 0) ? 'R' : 'L'; // Turning Right/Left
					} else {
						status_char = '='; // Near target
					}

					snprintf(display_str, sizeof(display_str),
							"L:%.0f N:%.0f E:%.1f%c", locked_heading,
							current_robot_front, heading_error, status_char);
				} else {
					// Show motor values
					snprintf(display_str, sizeof(display_str), "LF:%4d RF:%4d",
							motor_left_front, motor_right_front);
				}
				ssd1306_SetCursor(1, 24);
				ssd1306_WriteString(display_str, Font_7x10, White);

				// Line 4: PID output with overshoot indicator
				if (heading_lock_enabled && mode == MODE_MOVEMENT_HL) { // UPDATED
					snprintf(display_str, sizeof(display_str),
							"PID:%.1f BK:%4d%s", heading_pid_output, motor_back,
							overshoot_detected ? " OS" : "");
				} else {
					snprintf(display_str, sizeof(display_str), "BK:%4d",
							motor_back);
				}
				ssd1306_SetCursor(1, 36);
				ssd1306_WriteString(display_str, Font_7x10, White);

				// Line 5: Exception and I2C error information
				if (exception_info.exception_count > 0) {
					const char *exc_names[] = {"", "HF", "MF", "BF", "UF", "AS", "I2C"};
					uint32_t time_since = HAL_GetTick() - exception_info.last_exception_time;

					if (time_since < 60000) { // Show for 60 seconds
						if (exception_info.last_exception_type == EXCEPTION_I2C_ERROR) {
							// Show detailed I2C error
							snprintf(display_str, sizeof(display_str),
									"I2C:0x%lX #%lu %lus",
									exception_info.last_i2c_error,
									exception_info.i2c_error_count,
									time_since / 1000);
						} else {
							// Show other exception types
							snprintf(display_str, sizeof(display_str),
									"EXC:%s #%lu %lus ago",
									(exception_info.last_exception_type < 7) ?
										exc_names[exception_info.last_exception_type] : "??",
									exception_info.exception_count,
									time_since / 1000);
						}
					} else {
						// Show system uptime and heap status
						snprintf(display_str, sizeof(display_str),
								"Up:%lus Heap:%u",
								HAL_GetTick() / 1000,
								xPortGetFreeHeapSize());
					}
				} else {
					// No exceptions - show system uptime and heap status
					snprintf(display_str, sizeof(display_str),
							"Up:%lus Heap:%u",
							HAL_GetTick() / 1000,
							xPortGetFreeHeapSize());
				}
				ssd1306_SetCursor(1, 48);
				ssd1306_WriteString(display_str, Font_7x10, White);

			} else {
				// SBUS signal lost - show warning
				snprintf(display_str, sizeof(display_str), "SBUS SIGNAL LOST");
				ssd1306_SetCursor(1, 12);
				ssd1306_WriteString(display_str, Font_7x10, White);

				snprintf(display_str, sizeof(display_str), "MOTORS STOPPED");
				ssd1306_SetCursor(1, 24);
				ssd1306_WriteString(display_str, Font_7x10, White);

				snprintf(display_str, sizeof(display_str), "FOR SAFETY");
				ssd1306_SetCursor(1, 36);
				ssd1306_WriteString(display_str, Font_7x10, White);

				// Line 5: Exception information even when SBUS lost
				if (exception_info.exception_count > 0) {
					const char *exc_names[] = {"", "HF", "MF", "BF", "UF", "AS", "I2C"};
					if (exception_info.last_exception_type == EXCEPTION_I2C_ERROR) {
						snprintf(display_str, sizeof(display_str),
								"I2C:0x%lX #%lu",
								exception_info.last_i2c_error,
								exception_info.i2c_error_count);
					} else {
						snprintf(display_str, sizeof(display_str),
								"EXC:%s #%lu",
								(exception_info.last_exception_type < 7) ?
									exc_names[exception_info.last_exception_type] : "??",
								exception_info.exception_count);
					}
				} else {
					snprintf(display_str, sizeof(display_str), "No Exceptions");
				}
				ssd1306_SetCursor(1, 48);
				ssd1306_WriteString(display_str, Font_7x10, White);
			}
			break;

		case MODE_COUNT:
		default:
			// Handle invalid mode - should never happen
			snprintf(display_str, sizeof(display_str), "INVALID MODE");
			ssd1306_SetCursor(1, 12);
			ssd1306_WriteString(display_str, Font_7x10, White);
			break;
		}

		ssd1306_UpdateScreen(&hi2c1);
		//osDelay(100);
		osDelay(200); // Update display every 200ms (5Hz) for smoother updates
	}
  /* USER CODE END StartDisplayTask */
}

void StartEncoderTask(void *argument)
{
  /* USER CODE BEGIN StartEncoderTask */
	int32_t last_count = 0;
	robot_mode_t temp_mode = MODE_DISPLAY_SENSORS;
	/* Infinite loop */
	for (;;) {
		osMutexAcquire(EncoderMutexHandle, osWaitForever);
		int32_t count = encoder_count;
		uint8_t button = encoder_button_pressed;
		if (button)
			encoder_button_pressed = 0;
		osMutexRelease(EncoderMutexHandle);

		if (count != last_count) {
			// Handle encoder movement - change mode selection
			int32_t diff = count - last_count;
			last_count = count;

			osMutexAcquire(ModeMutexHandle, osWaitForever);
			robot_state_t state = robot_state;
			osMutexRelease(ModeMutexHandle);

			// Only allow mode change when robot is idle
			if (state == STATE_IDLE) {
				if (diff > 0) {
					temp_mode = (robot_mode_t) ((temp_mode + 1) % MODE_COUNT);
				} else {
					temp_mode = (robot_mode_t) ((temp_mode + MODE_COUNT - 1)
							% MODE_COUNT);
				}

				// Update the shared selected_mode variable
				osMutexAcquire(ModeMutexHandle, osWaitForever);
				selected_mode = temp_mode;
				osMutexRelease(ModeMutexHandle);
			}
		}

		if (button) {
			// Handle button press
			osMutexAcquire(ModeMutexHandle, osWaitForever);
			robot_mode_t current = current_mode;
			robot_state_t state = robot_state;

			if (state == STATE_IDLE) {
				// If idle, either change mode or start movement (for movement modes)
				if (temp_mode != current) {
					// Change mode
					current_mode = temp_mode;
					selected_mode = temp_mode;  // Keep them in sync
					mode_change_request = 1;
				} else if (current == MODE_MOVEMENT // UPDATED
						|| current == MODE_MOVEMENT_HL) { // UPDATED
					// Start movement
					robot_state = STATE_RUNNING;
					state_toggle_request = 1;
				}
			} else {
				// If running, stop movement
				robot_state = STATE_IDLE;
				state_toggle_request = 1;
			}
			osMutexRelease(ModeMutexHandle);
		}
		//osDelay(10);
		osDelay(20); // Update encoder every 20ms (50Hz)
	}
  /* USER CODE END StartEncoderTask */
}

void HAL_TIM_PeriodElapsedCallback(TIM_HandleTypeDef *htim)
{
  if (htim->Instance == TIM2)
  {
    HAL_IncTick();
  }
}

void Error_Handler(void)
{
  /* USER CODE BEGIN Error_Handler_Debug */
	/* User can add his own implementation to report the HAL error return state */

	// Don't disable interrupts - allow system to continue
	// __disable_irq();  // ❌ REMOVE THIS LINE
	// Enable GPIOC clock if not already enabled
	__HAL_RCC_GPIOC_CLK_ENABLE();

	// Turn ON internal LED to indicate error (PC13 is active LOW)
	HAL_GPIO_WritePin(GPIOC, GPIO_PIN_13, GPIO_PIN_RESET);

	// Print detailed error information
	printf("\r\n=== ERROR HANDLER ENTERED ===\r\n");
	printf("System Tick: %lu ms\r\n", HAL_GetTick());

	// Print current task info if FreeRTOS is running
	if (osKernelGetState() == osKernelRunning) {
		printf("Current Task: %s\r\n", osThreadGetName(osThreadGetId()));
		printf("Free Heap: %u bytes\r\n", xPortGetFreeHeapSize());
	} else {
		printf("FreeRTOS State: %d\r\n", osKernelGetState());
	}

	// Print peripheral error states
	printf("UART1 Error: 0x%08lX\r\n", huart1.ErrorCode);
	printf("UART2 Error: 0x%08lX\r\n", huart2.ErrorCode);
	printf("I2C1 Error: 0x%08lX\r\n", hi2c1.ErrorCode);

	// Print SBUS status
	printf("SBUS Valid: %d\r\n", sbus_signal_valid);
	printf("SBUS Last Valid: %lu ms ago\r\n", HAL_GetTick() - sbus_last_valid_time);

	// Print current mode and state
	printf("Current Mode: %d, State: %d\r\n", current_mode, robot_state);
	printf("Heading Lock: %d\r\n", heading_lock_enabled);

	printf("=== END ERROR INFO ===\r\n\r\n");

	// Flash LED to indicate error, but don't get stuck
	for (int i = 0; i < 10; i++) {  // Flash 10 times then continue
		HAL_GPIO_TogglePin(GPIOC, GPIO_PIN_13);
		HAL_Delay(100);  // Shorter delay
	}

	// Keep LED ON after flashing to indicate persistent error state
	HAL_GPIO_WritePin(GPIOC, GPIO_PIN_13, GPIO_PIN_RESET);

	// Instead of infinite loop, try to recover
	// Reset system if this is a critical error
	printf("Critical error occurred, resetting system...\r\n");
	HAL_Delay(100); // Give time for printf to complete
	NVIC_SystemReset();
  /* USER CODE END Error_Handler_Debug */
}

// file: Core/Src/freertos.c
/* USER CODE BEGIN Header */
/**
  ******************************************************************************
  * File Name          : freertos.c
  * Description        : Code for freertos applications
  ******************************************************************************
  * @attention
  *
  * Copyright (c) 2025 STMicroelectronics.
  * All rights reserved.
  *
  * This software is licensed under terms that can be found in the LICENSE file
  * in the root directory of this software component.
  * If no LICENSE file comes with this software, it is provided AS-IS.
  *
  ******************************************************************************
  */
/* USER CODE END Header */

#include "FreeRTOS.h"
#include "task.h"
#include "main.h"

/* Hook prototypes */
void configureTimerForRunTimeStats(void);
unsigned long getRunTimeCounterValue(void);
void vApplicationStackOverflowHook(TaskHandle_t xTask, signed char *pcTaskName);

/* USER CODE BEGIN 1 */
/* Functions needed when configGENERATE_RUN_TIME_STATS is on */
__weak void configureTimerForRunTimeStats(void)
{

}

__weak unsigned long getRunTimeCounterValue(void)
{
return 0;
}
/* USER CODE END 1 */

/* USER CODE BEGIN 4 */
void vApplicationStackOverflowHook(TaskHandle_t xTask, signed char *pcTaskName)
{
   /* Run time stack overflow checking is performed if
   configCHECK_FOR_STACK_OVERFLOW is defined to 1 or 2. This hook function is
   called if a stack overflow is detected. */
}
/* USER CODE END 4 */
